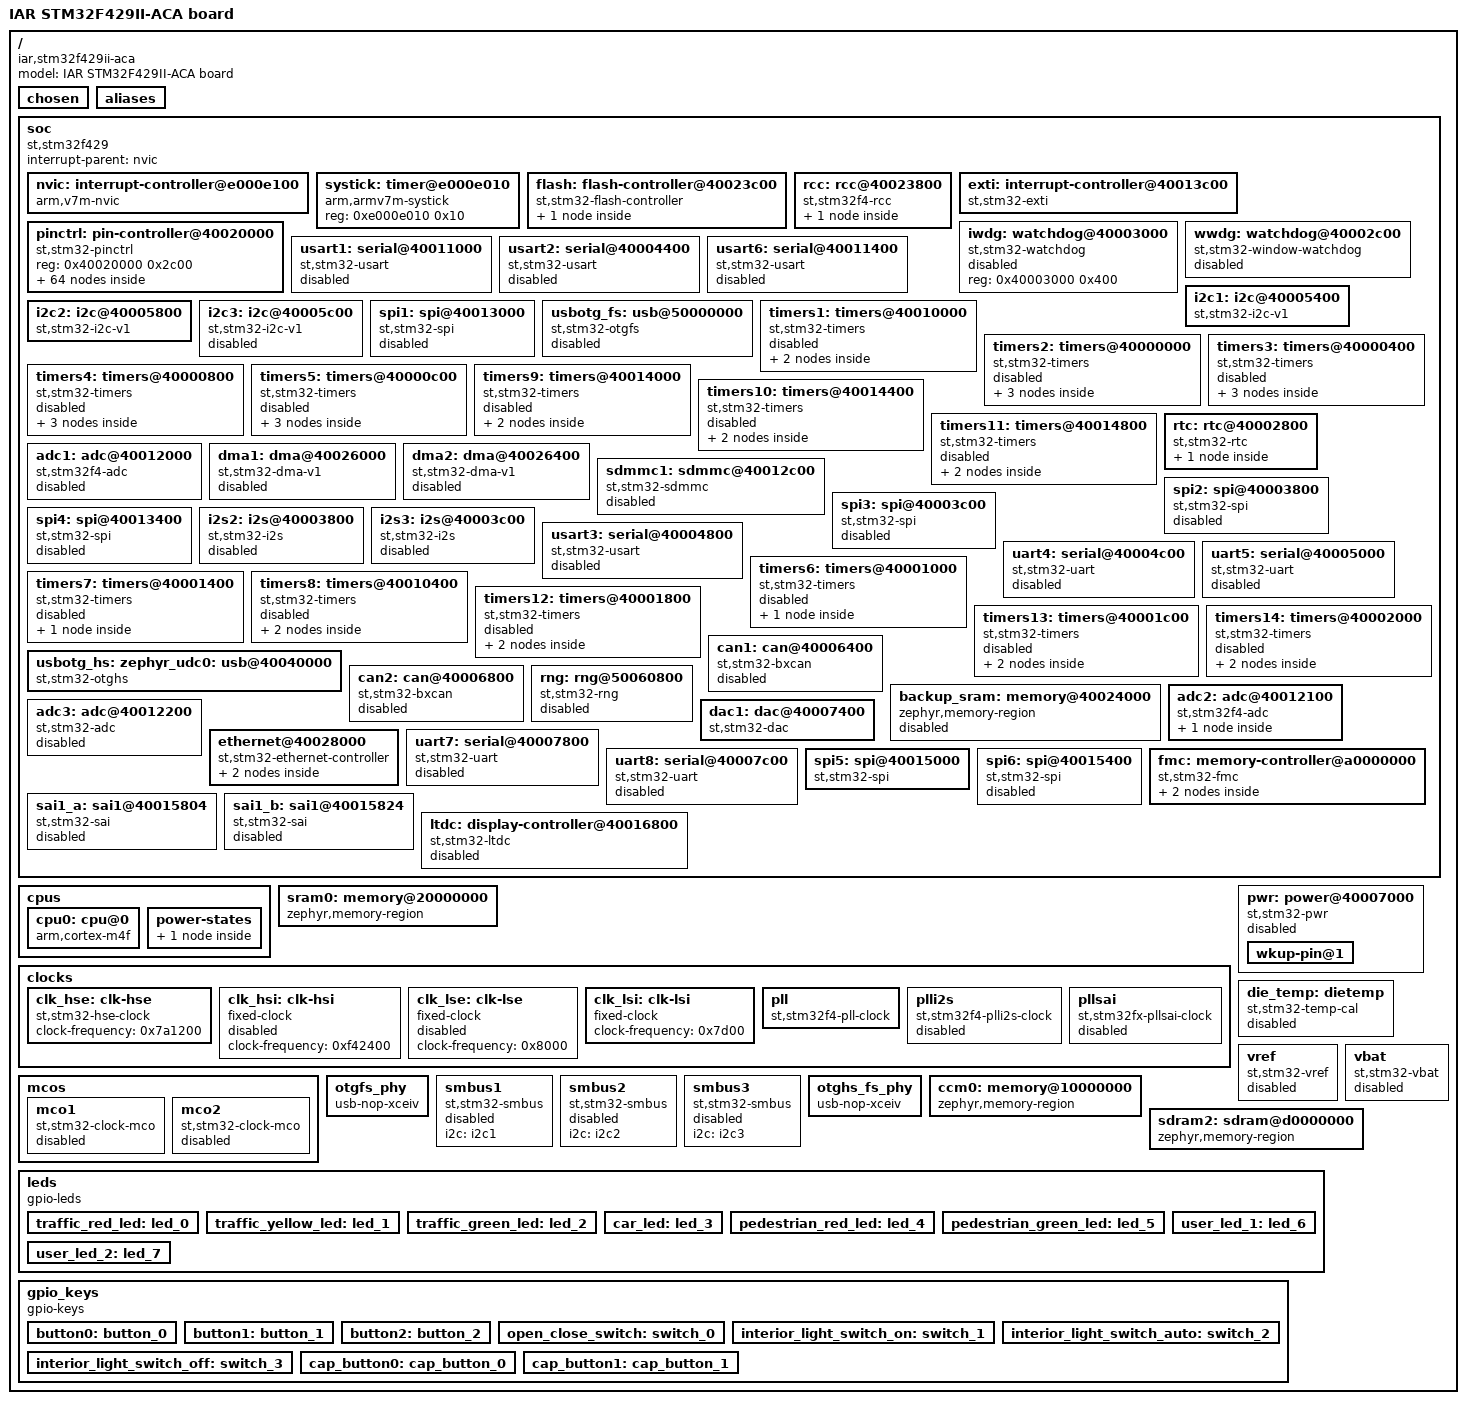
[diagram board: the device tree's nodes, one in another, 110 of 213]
/dts-v1/;

/* node '/' defined in zephyr/dts/common/skeleton.dtsi:9 */
/ {
	#address-cells = < 0x1 >;            /* in zephyr/dts/common/skeleton.dtsi:10 */
	#size-cells = < 0x1 >;               /* in zephyr/dts/common/skeleton.dtsi:11 */
	model = "IAR STM32F429II-ACA board"; /* in zephyr/boards/iar/stm32f429ii_aca/stm32f429ii_aca.dts:15 */
	compatible = "iar,stm32f429ii-aca";  /* in zephyr/boards/iar/stm32f429ii_aca/stm32f429ii_aca.dts:16 */

	/* node '/chosen' defined in zephyr/dts/common/skeleton.dtsi:13 */
	chosen {
		zephyr,flash-controller = &flash;  /* in zephyr/dts/arm/st/f4/stm32f4.dtsi:27 */
		zephyr,cortex-m-idle-timer = &rtc; /* in zephyr/dts/arm/st/f4/stm32f4.dtsi:28 */
		zephyr,entropy = &rng;             /* in zephyr/dts/arm/st/f4/stm32f405.dtsi:13 */
		zephyr,sram = &sram0;              /* in zephyr/boards/iar/stm32f429ii_aca/stm32f429ii_aca.dts:19 */
		zephyr,flash = &flash0;            /* in zephyr/boards/iar/stm32f429ii_aca/stm32f429ii_aca.dts:20 */
		zephyr,ccm = &ccm0;                /* in zephyr/boards/iar/stm32f429ii_aca/stm32f429ii_aca.dts:21 */
	};

	/* node '/aliases' defined in zephyr/dts/common/skeleton.dtsi:15 */
	aliases {
		led0 = &traffic_red_led;           /* in zephyr/boards/iar/stm32f429ii_aca/stm32f429ii_aca.dts:134 */
		led1 = &traffic_yellow_led;        /* in zephyr/boards/iar/stm32f429ii_aca/stm32f429ii_aca.dts:135 */
		led2 = &traffic_green_led;         /* in zephyr/boards/iar/stm32f429ii_aca/stm32f429ii_aca.dts:136 */
		led3 = &car_led;                   /* in zephyr/boards/iar/stm32f429ii_aca/stm32f429ii_aca.dts:137 */
		led4 = &pedestrian_red_led;        /* in zephyr/boards/iar/stm32f429ii_aca/stm32f429ii_aca.dts:138 */
		led5 = &pedestrian_green_led;      /* in zephyr/boards/iar/stm32f429ii_aca/stm32f429ii_aca.dts:139 */
		led6 = &user_led_1;                /* in zephyr/boards/iar/stm32f429ii_aca/stm32f429ii_aca.dts:140 */
		led7 = &user_led_2;                /* in zephyr/boards/iar/stm32f429ii_aca/stm32f429ii_aca.dts:141 */
		sw0 = &button0;                    /* in zephyr/boards/iar/stm32f429ii_aca/stm32f429ii_aca.dts:142 */
		sw1 = &button1;                    /* in zephyr/boards/iar/stm32f429ii_aca/stm32f429ii_aca.dts:143 */
		sw2 = &button2;                    /* in zephyr/boards/iar/stm32f429ii_aca/stm32f429ii_aca.dts:144 */
		sw3 = &open_close_switch;          /* in zephyr/boards/iar/stm32f429ii_aca/stm32f429ii_aca.dts:145 */
		sw4 = &interior_light_switch_on;   /* in zephyr/boards/iar/stm32f429ii_aca/stm32f429ii_aca.dts:146 */
		sw5 = &interior_light_switch_auto; /* in zephyr/boards/iar/stm32f429ii_aca/stm32f429ii_aca.dts:147 */
		sw6 = &interior_light_switch_off;  /* in zephyr/boards/iar/stm32f429ii_aca/stm32f429ii_aca.dts:148 */
		sw7 = &cap_button0;                /* in zephyr/boards/iar/stm32f429ii_aca/stm32f429ii_aca.dts:149 */
		sw8 = &cap_button1;                /* in zephyr/boards/iar/stm32f429ii_aca/stm32f429ii_aca.dts:150 */
	};

	/* node '/soc' defined in zephyr/dts/arm/armv7-m.dtsi:6 */
	soc {
		#address-cells = < 0x1 >;     /* in zephyr/dts/arm/armv7-m.dtsi:7 */
		#size-cells = < 0x1 >;        /* in zephyr/dts/arm/armv7-m.dtsi:8 */
		interrupt-parent = < &nvic >; /* in zephyr/dts/arm/armv7-m.dtsi:10 */
		ranges;                       /* in zephyr/dts/arm/armv7-m.dtsi:11 */
		compatible = "st,stm32f429",
		             "st,stm32f4",
		             "simple-bus";    /* in zephyr/dts/arm/st/f4/stm32f429.dtsi:12 */

		/* node '/soc/interrupt-controller@e000e100' defined in zephyr/dts/arm/armv7-m.dtsi:13 */
		nvic: interrupt-controller@e000e100 {
			#address-cells = < 0x1 >;            /* in zephyr/dts/arm/armv7-m.dtsi:14 */
			compatible = "arm,v7m-nvic";         /* in zephyr/dts/arm/armv7-m.dtsi:15 */
			reg = < 0xe000e100 0xc00 >;          /* in zephyr/dts/arm/armv7-m.dtsi:16 */
			interrupt-controller;                /* in zephyr/dts/arm/armv7-m.dtsi:17 */
			#interrupt-cells = < 0x2 >;          /* in zephyr/dts/arm/armv7-m.dtsi:18 */
			arm,num-irq-priority-bits = < 0x4 >; /* in zephyr/dts/arm/st/f4/stm32f4.dtsi:676 */
			phandle = < 0x1 >;                   /* in zephyr/dts/arm/armv7-m.dtsi:10 */
		};

		/* node '/soc/timer@e000e010' defined in zephyr/dts/arm/armv7-m.dtsi:21 */
		systick: timer@e000e010 {
			compatible = "arm,armv7m-systick"; /* in zephyr/dts/arm/armv7-m.dtsi:22 */
			reg = < 0xe000e010 0x10 >;         /* in zephyr/dts/arm/armv7-m.dtsi:23 */
		};

		/* node '/soc/flash-controller@40023c00' defined in zephyr/dts/arm/st/f4/stm32f4.dtsi:111 */
		flash: flash-controller@40023c00 {
			compatible = "st,stm32-flash-controller",
			             "st,stm32f4-flash-controller"; /* in zephyr/dts/arm/st/f4/stm32f4.dtsi:112 */
			reg = < 0x40023c00 0x400 >;                 /* in zephyr/dts/arm/st/f4/stm32f4.dtsi:113 */
			interrupts = < 0x4 0x0 >;                   /* in zephyr/dts/arm/st/f4/stm32f4.dtsi:114 */
			#address-cells = < 0x1 >;                   /* in zephyr/dts/arm/st/f4/stm32f4.dtsi:116 */
			#size-cells = < 0x1 >;                      /* in zephyr/dts/arm/st/f4/stm32f4.dtsi:117 */

			/* node '/soc/flash-controller@40023c00/flash@8000000' defined in zephyr/dts/arm/st/f4/stm32f4.dtsi:119 */
			flash0: flash@8000000 {
				compatible = "st,stm32f4-nv-flash",
				             "st,stm32-nv-flash",
				             "soc-nv-flash";        /* in zephyr/dts/arm/st/f4/stm32f4.dtsi:120 */
				write-block-size = < 0x1 >;         /* in zephyr/dts/arm/st/f4/stm32f4.dtsi:123 */
				max-erase-time = < 0xfa0 >;         /* in zephyr/dts/arm/st/f4/stm32f4.dtsi:125 */
				reg = < 0x8000000 0x200000 >;       /* in zephyr/dts/arm/st/f4/stm32f429Xi.dtsi:23 */
			};
		};

		/* node '/soc/rcc@40023800' defined in zephyr/dts/arm/st/f4/stm32f4.dtsi:129 */
		rcc: rcc@40023800 {
			#clock-cells = < 0x2 >;          /* in zephyr/dts/arm/st/f4/stm32f4.dtsi:131 */
			reg = < 0x40023800 0x400 >;      /* in zephyr/dts/arm/st/f4/stm32f4.dtsi:132 */
			compatible = "st,stm32f4-rcc";   /* in zephyr/dts/arm/st/f4/stm32f427.dtsi:25 */
			clocks = < &pll >;               /* in zephyr/boards/iar/stm32f429ii_aca/stm32f429ii_aca.dts:173 */
			clock-frequency = < 0xa037a00 >; /* in zephyr/boards/iar/stm32f429ii_aca/stm32f429ii_aca.dts:174 */
			ahb-prescaler = < 0x1 >;         /* in zephyr/boards/iar/stm32f429ii_aca/stm32f429ii_aca.dts:175 */
			apb1-prescaler = < 0x4 >;        /* in zephyr/boards/iar/stm32f429ii_aca/stm32f429ii_aca.dts:176 */
			apb2-prescaler = < 0x2 >;        /* in zephyr/boards/iar/stm32f429ii_aca/stm32f429ii_aca.dts:177 */
			phandle = < 0x3 >;               /* in zephyr/dts/arm/st/f4/stm32f4.dtsi:146 */

			/* node '/soc/rcc@40023800/reset-controller' defined in zephyr/dts/arm/st/f4/stm32f4.dtsi:134 */
			rctl: reset-controller {
				compatible = "st,stm32-rcc-rctl"; /* in zephyr/dts/arm/st/f4/stm32f4.dtsi:135 */
				#reset-cells = < 0x1 >;           /* in zephyr/dts/arm/st/f4/stm32f4.dtsi:136 */
				phandle = < 0x4 >;                /* in zephyr/dts/arm/st/f4/stm32f4.dtsi:245 */
			};
		};

		/* node '/soc/interrupt-controller@40013c00' defined in zephyr/dts/arm/st/f4/stm32f4.dtsi:140 */
		exti: interrupt-controller@40013c00 {
			compatible = "st,stm32-exti";  /* in zephyr/dts/arm/st/f4/stm32f4.dtsi:141 */
			interrupt-controller;          /* in zephyr/dts/arm/st/f4/stm32f4.dtsi:142 */
			#interrupt-cells = < 0x1 >;    /* in zephyr/dts/arm/st/f4/stm32f4.dtsi:143 */
			#address-cells = < 0x0 >;      /* in zephyr/dts/arm/st/f4/stm32f4.dtsi:144 */
			reg = < 0x40013c00 0x400 >;    /* in zephyr/dts/arm/st/f4/stm32f4.dtsi:145 */
			clocks = < &rcc 0x44 0x4000 >; /* in zephyr/dts/arm/st/f4/stm32f4.dtsi:146 */
			num-lines = < 0x20 >;          /* in zephyr/dts/arm/st/f4/stm32f4.dtsi:147 */
			interrupts = < 0x6 0x0 >,
			             < 0x7 0x0 >,
			             < 0x8 0x0 >,
			             < 0x9 0x0 >,
			             < 0xa 0x0 >,
			             < 0x17 0x0 >,
			             < 0x28 0x0 >;     /* in zephyr/dts/arm/st/f4/stm32f4.dtsi:148 */
			interrupt-names = "line0",
			                  "line1",
			                  "line2",
			                  "line3",
			                  "line4",
			                  "line5-9",
			                  "line10-15"; /* in zephyr/dts/arm/st/f4/stm32f4.dtsi:150 */
			line-ranges = < 0x0 0x1 >,
			              < 0x1 0x1 >,
			              < 0x2 0x1 >,
			              < 0x3 0x1 >,
			              < 0x4 0x1 >,
			              < 0x5 0x5 >,
			              < 0xa 0x6 >;     /* in zephyr/dts/arm/st/f4/stm32f4.dtsi:152 */
		};

		/* node '/soc/pin-controller@40020000' defined in zephyr/dts/arm/st/f4/stm32f4.dtsi:156 */
		pinctrl: pin-controller@40020000 {
			compatible = "st,stm32-pinctrl"; /* in zephyr/dts/arm/st/f4/stm32f4.dtsi:157 */
			#address-cells = < 0x1 >;        /* in zephyr/dts/arm/st/f4/stm32f4.dtsi:158 */
			#size-cells = < 0x1 >;           /* in zephyr/dts/arm/st/f4/stm32f4.dtsi:159 */
			reg = < 0x40020000 0x2c00 >;     /* in zephyr/dts/arm/st/f4/stm32f427.dtsi:29 */

			/* node '/soc/pin-controller@40020000/gpio@40020000' defined in zephyr/dts/arm/st/f4/stm32f4.dtsi:162 */
			gpioa: gpio@40020000 {
				compatible = "st,stm32-gpio"; /* in zephyr/dts/arm/st/f4/stm32f4.dtsi:163 */
				gpio-controller;              /* in zephyr/dts/arm/st/f4/stm32f4.dtsi:164 */
				#gpio-cells = < 0x2 >;        /* in zephyr/dts/arm/st/f4/stm32f4.dtsi:165 */
				reg = < 0x40020000 0x400 >;   /* in zephyr/dts/arm/st/f4/stm32f4.dtsi:166 */
				clocks = < &rcc 0x30 0x1 >;   /* in zephyr/dts/arm/st/f4/stm32f4.dtsi:167 */
				phandle = < 0x41 >;           /* in zephyr/dts/arm/st/f4/stm32f4.dtsi:615 */
			};

			/* node '/soc/pin-controller@40020000/gpio@40020400' defined in zephyr/dts/arm/st/f4/stm32f4.dtsi:170 */
			gpiob: gpio@40020400 {
				compatible = "st,stm32-gpio"; /* in zephyr/dts/arm/st/f4/stm32f4.dtsi:171 */
				gpio-controller;              /* in zephyr/dts/arm/st/f4/stm32f4.dtsi:172 */
				#gpio-cells = < 0x2 >;        /* in zephyr/dts/arm/st/f4/stm32f4.dtsi:173 */
				reg = < 0x40020400 0x400 >;   /* in zephyr/dts/arm/st/f4/stm32f4.dtsi:174 */
				clocks = < &rcc 0x30 0x2 >;   /* in zephyr/dts/arm/st/f4/stm32f4.dtsi:175 */
			};

			/* node '/soc/pin-controller@40020000/gpio@40020800' defined in zephyr/dts/arm/st/f4/stm32f4.dtsi:178 */
			gpioc: gpio@40020800 {
				compatible = "st,stm32-gpio"; /* in zephyr/dts/arm/st/f4/stm32f4.dtsi:179 */
				gpio-controller;              /* in zephyr/dts/arm/st/f4/stm32f4.dtsi:180 */
				#gpio-cells = < 0x2 >;        /* in zephyr/dts/arm/st/f4/stm32f4.dtsi:181 */
				reg = < 0x40020800 0x400 >;   /* in zephyr/dts/arm/st/f4/stm32f4.dtsi:182 */
				clocks = < &rcc 0x30 0x4 >;   /* in zephyr/dts/arm/st/f4/stm32f4.dtsi:183 */
				phandle = < 0x15 >;           /* in zephyr/boards/iar/stm32f429ii_aca/stm32f429ii_aca.dts:205 */
			};

			/* node '/soc/pin-controller@40020000/gpio@40020c00' defined in zephyr/dts/arm/st/f4/stm32f4.dtsi:186 */
			gpiod: gpio@40020c00 {
				compatible = "st,stm32-gpio"; /* in zephyr/dts/arm/st/f4/stm32f4.dtsi:187 */
				gpio-controller;              /* in zephyr/dts/arm/st/f4/stm32f4.dtsi:188 */
				#gpio-cells = < 0x2 >;        /* in zephyr/dts/arm/st/f4/stm32f4.dtsi:189 */
				reg = < 0x40020c00 0x400 >;   /* in zephyr/dts/arm/st/f4/stm32f4.dtsi:190 */
				clocks = < &rcc 0x30 0x8 >;   /* in zephyr/dts/arm/st/f4/stm32f4.dtsi:191 */
				phandle = < 0x46 >;           /* in zephyr/boards/iar/stm32f429ii_aca/stm32f429ii_aca.dts:40 */
			};

			/* node '/soc/pin-controller@40020000/gpio@40021000' defined in zephyr/dts/arm/st/f4/stm32f4.dtsi:194 */
			gpioe: gpio@40021000 {
				compatible = "st,stm32-gpio"; /* in zephyr/dts/arm/st/f4/stm32f4.dtsi:195 */
				gpio-controller;              /* in zephyr/dts/arm/st/f4/stm32f4.dtsi:196 */
				#gpio-cells = < 0x2 >;        /* in zephyr/dts/arm/st/f4/stm32f4.dtsi:197 */
				reg = < 0x40021000 0x400 >;   /* in zephyr/dts/arm/st/f4/stm32f4.dtsi:198 */
				clocks = < &rcc 0x30 0x10 >;  /* in zephyr/dts/arm/st/f4/stm32f4.dtsi:199 */
			};

			/* node '/soc/pin-controller@40020000/gpio@40021400' defined in zephyr/dts/arm/st/f4/stm32f4.dtsi:202 */
			gpiof: gpio@40021400 {
				compatible = "st,stm32-gpio"; /* in zephyr/dts/arm/st/f4/stm32f405.dtsi:27 */
				gpio-controller;              /* in zephyr/dts/arm/st/f4/stm32f405.dtsi:28 */
				#gpio-cells = < 0x2 >;        /* in zephyr/dts/arm/st/f4/stm32f405.dtsi:29 */
				reg = < 0x40021400 0x400 >;   /* in zephyr/dts/arm/st/f4/stm32f405.dtsi:30 */
				clocks = < &rcc 0x30 0x20 >;  /* in zephyr/dts/arm/st/f4/stm32f405.dtsi:31 */
			};

			/* node '/soc/pin-controller@40020000/gpio@40021800' defined in zephyr/dts/arm/st/f4/stm32f4.dtsi:210 */
			gpiog: gpio@40021800 {
				compatible = "st,stm32-gpio"; /* in zephyr/dts/arm/st/f4/stm32f405.dtsi:35 */
				gpio-controller;              /* in zephyr/dts/arm/st/f4/stm32f405.dtsi:36 */
				#gpio-cells = < 0x2 >;        /* in zephyr/dts/arm/st/f4/stm32f405.dtsi:37 */
				reg = < 0x40021800 0x400 >;   /* in zephyr/dts/arm/st/f4/stm32f405.dtsi:38 */
				clocks = < &rcc 0x30 0x40 >;  /* in zephyr/dts/arm/st/f4/stm32f405.dtsi:39 */
				phandle = < 0x47 >;           /* in zephyr/boards/iar/stm32f429ii_aca/stm32f429ii_aca.dts:92 */
			};

			/* node '/soc/pin-controller@40020000/gpio@40021c00' defined in zephyr/dts/arm/st/f4/stm32f4.dtsi:218 */
			gpioh: gpio@40021c00 {
				compatible = "st,stm32-gpio"; /* in zephyr/dts/arm/st/f4/stm32f4.dtsi:219 */
				gpio-controller;              /* in zephyr/dts/arm/st/f4/stm32f4.dtsi:220 */
				#gpio-cells = < 0x2 >;        /* in zephyr/dts/arm/st/f4/stm32f4.dtsi:221 */
				reg = < 0x40021c00 0x400 >;   /* in zephyr/dts/arm/st/f4/stm32f4.dtsi:222 */
				clocks = < &rcc 0x30 0x80 >;  /* in zephyr/dts/arm/st/f4/stm32f4.dtsi:223 */
				phandle = < 0x49 >;           /* in zephyr/boards/iar/stm32f429ii_aca/stm32f429ii_aca.dts:122 */
			};

			/* node '/soc/pin-controller@40020000/gpio@40022000' defined in zephyr/dts/arm/st/f4/stm32f405.dtsi:42 */
			gpioi: gpio@40022000 {
				compatible = "st,stm32-gpio"; /* in zephyr/dts/arm/st/f4/stm32f405.dtsi:43 */
				gpio-controller;              /* in zephyr/dts/arm/st/f4/stm32f405.dtsi:44 */
				#gpio-cells = < 0x2 >;        /* in zephyr/dts/arm/st/f4/stm32f405.dtsi:45 */
				reg = < 0x40022000 0x400 >;   /* in zephyr/dts/arm/st/f4/stm32f405.dtsi:46 */
				clocks = < &rcc 0x30 0x100 >; /* in zephyr/dts/arm/st/f4/stm32f405.dtsi:47 */
				phandle = < 0x48 >;           /* in zephyr/boards/iar/stm32f429ii_aca/stm32f429ii_aca.dts:98 */
			};

			/* node '/soc/pin-controller@40020000/gpio@40022400' defined in zephyr/dts/arm/st/f4/stm32f427.dtsi:31 */
			gpioj: gpio@40022400 {
				compatible = "st,stm32-gpio"; /* in zephyr/dts/arm/st/f4/stm32f427.dtsi:32 */
				gpio-controller;              /* in zephyr/dts/arm/st/f4/stm32f427.dtsi:33 */
				#gpio-cells = < 0x2 >;        /* in zephyr/dts/arm/st/f4/stm32f427.dtsi:34 */
				reg = < 0x40022400 0x400 >;   /* in zephyr/dts/arm/st/f4/stm32f427.dtsi:35 */
				clocks = < &rcc 0x30 0x200 >; /* in zephyr/dts/arm/st/f4/stm32f427.dtsi:36 */
			};

			/* node '/soc/pin-controller@40020000/gpio@40022800' defined in zephyr/dts/arm/st/f4/stm32f427.dtsi:39 */
			gpiok: gpio@40022800 {
				compatible = "st,stm32-gpio"; /* in zephyr/dts/arm/st/f4/stm32f427.dtsi:40 */
				gpio-controller;              /* in zephyr/dts/arm/st/f4/stm32f427.dtsi:41 */
				#gpio-cells = < 0x2 >;        /* in zephyr/dts/arm/st/f4/stm32f427.dtsi:42 */
				reg = < 0x40022800 0x400 >;   /* in zephyr/dts/arm/st/f4/stm32f427.dtsi:43 */
				clocks = < &rcc 0x30 0x400 >; /* in zephyr/dts/arm/st/f4/stm32f427.dtsi:44 */
			};

			/* node '/soc/pin-controller@40020000/adc2_in6_pa6' defined in modules/hal/stm32/dts/st/f4/stm32f429iitx-pinctrl.dtsi:103 */
			adc2_in6_pa6: adc2_in6_pa6 {
				pinmux = < 0xd0 >; /* in modules/hal/stm32/dts/st/f4/stm32f429iitx-pinctrl.dtsi:104 */
				phandle = < 0xf >; /* in zephyr/boards/iar/stm32f429ii_aca/stm32f429ii_aca.dts:249 */
			};

			/* node '/soc/pin-controller@40020000/dac_out2_pa5' defined in modules/hal/stm32/dts/st/f4/stm32f429iitx-pinctrl.dtsi:833 */
			dac_out2_pa5: dac_out2_pa5 {
				pinmux = < 0xb0 >;  /* in modules/hal/stm32/dts/st/f4/stm32f429iitx-pinctrl.dtsi:834 */
				phandle = < 0x10 >; /* in zephyr/boards/iar/stm32f429ii_aca/stm32f429ii_aca.dts:267 */
			};

			/* node '/soc/pin-controller@40020000/fmc_sdnwe_pc0' defined in modules/hal/stm32/dts/st/f4/stm32f429iitx-pinctrl.dtsi:1256 */
			fmc_sdnwe_pc0: fmc_sdnwe_pc0 {
				pinmux = < 0x40c >;            /* in modules/hal/stm32/dts/st/f4/stm32f429iitx-pinctrl.dtsi:1257 */
				bias-pull-up;                  /* in modules/hal/stm32/dts/st/f4/stm32f429iitx-pinctrl.dtsi:1258 */
				slew-rate = "very-high-speed"; /* in modules/hal/stm32/dts/st/f4/stm32f429iitx-pinctrl.dtsi:1259 */
				phandle = < 0x19 >;            /* in zephyr/boards/iar/stm32f429ii_aca/stm32f429ii_aca.dts:210 */
			};

			/* node '/soc/pin-controller@40020000/fmc_sdne0_pc2' defined in modules/hal/stm32/dts/st/f4/stm32f429iitx-pinctrl.dtsi:1262 */
			fmc_sdne0_pc2: fmc_sdne0_pc2 {
				pinmux = < 0x44c >;            /* in modules/hal/stm32/dts/st/f4/stm32f429iitx-pinctrl.dtsi:1263 */
				bias-pull-up;                  /* in modules/hal/stm32/dts/st/f4/stm32f429iitx-pinctrl.dtsi:1264 */
				slew-rate = "very-high-speed"; /* in modules/hal/stm32/dts/st/f4/stm32f429iitx-pinctrl.dtsi:1265 */
				phandle = < 0x1b >;            /* in zephyr/boards/iar/stm32f429ii_aca/stm32f429ii_aca.dts:210 */
			};

			/* node '/soc/pin-controller@40020000/fmc_sdcke0_pc3' defined in modules/hal/stm32/dts/st/f4/stm32f429iitx-pinctrl.dtsi:1268 */
			fmc_sdcke0_pc3: fmc_sdcke0_pc3 {
				pinmux = < 0x46c >;            /* in modules/hal/stm32/dts/st/f4/stm32f429iitx-pinctrl.dtsi:1269 */
				bias-pull-up;                  /* in modules/hal/stm32/dts/st/f4/stm32f429iitx-pinctrl.dtsi:1270 */
				slew-rate = "very-high-speed"; /* in modules/hal/stm32/dts/st/f4/stm32f429iitx-pinctrl.dtsi:1271 */
				phandle = < 0x1a >;            /* in zephyr/boards/iar/stm32f429ii_aca/stm32f429ii_aca.dts:210 */
			};

			/* node '/soc/pin-controller@40020000/fmc_d2_pd0' defined in modules/hal/stm32/dts/st/f4/stm32f429iitx-pinctrl.dtsi:1274 */
			fmc_d2_pd0: fmc_d2_pd0 {
				pinmux = < 0x60c >;            /* in modules/hal/stm32/dts/st/f4/stm32f429iitx-pinctrl.dtsi:1275 */
				bias-pull-up;                  /* in modules/hal/stm32/dts/st/f4/stm32f429iitx-pinctrl.dtsi:1276 */
				slew-rate = "very-high-speed"; /* in modules/hal/stm32/dts/st/f4/stm32f429iitx-pinctrl.dtsi:1277 */
				phandle = < 0x30 >;            /* in zephyr/boards/iar/stm32f429ii_aca/stm32f429ii_aca.dts:210 */
			};

			/* node '/soc/pin-controller@40020000/fmc_d3_pd1' defined in modules/hal/stm32/dts/st/f4/stm32f429iitx-pinctrl.dtsi:1280 */
			fmc_d3_pd1: fmc_d3_pd1 {
				pinmux = < 0x62c >;            /* in modules/hal/stm32/dts/st/f4/stm32f429iitx-pinctrl.dtsi:1281 */
				bias-pull-up;                  /* in modules/hal/stm32/dts/st/f4/stm32f429iitx-pinctrl.dtsi:1282 */
				slew-rate = "very-high-speed"; /* in modules/hal/stm32/dts/st/f4/stm32f429iitx-pinctrl.dtsi:1283 */
				phandle = < 0x31 >;            /* in zephyr/boards/iar/stm32f429ii_aca/stm32f429ii_aca.dts:210 */
			};

			/* node '/soc/pin-controller@40020000/fmc_d13_pd8' defined in modules/hal/stm32/dts/st/f4/stm32f429iitx-pinctrl.dtsi:1316 */
			fmc_d13_pd8: fmc_d13_pd8 {
				pinmux = < 0x70c >;            /* in modules/hal/stm32/dts/st/f4/stm32f429iitx-pinctrl.dtsi:1317 */
				bias-pull-up;                  /* in modules/hal/stm32/dts/st/f4/stm32f429iitx-pinctrl.dtsi:1318 */
				slew-rate = "very-high-speed"; /* in modules/hal/stm32/dts/st/f4/stm32f429iitx-pinctrl.dtsi:1319 */
				phandle = < 0x3b >;            /* in zephyr/boards/iar/stm32f429ii_aca/stm32f429ii_aca.dts:210 */
			};

			/* node '/soc/pin-controller@40020000/fmc_d14_pd9' defined in modules/hal/stm32/dts/st/f4/stm32f429iitx-pinctrl.dtsi:1322 */
			fmc_d14_pd9: fmc_d14_pd9 {
				pinmux = < 0x72c >;            /* in modules/hal/stm32/dts/st/f4/stm32f429iitx-pinctrl.dtsi:1323 */
				bias-pull-up;                  /* in modules/hal/stm32/dts/st/f4/stm32f429iitx-pinctrl.dtsi:1324 */
				slew-rate = "very-high-speed"; /* in modules/hal/stm32/dts/st/f4/stm32f429iitx-pinctrl.dtsi:1325 */
				phandle = < 0x3c >;            /* in zephyr/boards/iar/stm32f429ii_aca/stm32f429ii_aca.dts:210 */
			};

			/* node '/soc/pin-controller@40020000/fmc_d15_pd10' defined in modules/hal/stm32/dts/st/f4/stm32f429iitx-pinctrl.dtsi:1328 */
			fmc_d15_pd10: fmc_d15_pd10 {
				pinmux = < 0x74c >;            /* in modules/hal/stm32/dts/st/f4/stm32f429iitx-pinctrl.dtsi:1329 */
				bias-pull-up;                  /* in modules/hal/stm32/dts/st/f4/stm32f429iitx-pinctrl.dtsi:1330 */
				slew-rate = "very-high-speed"; /* in modules/hal/stm32/dts/st/f4/stm32f429iitx-pinctrl.dtsi:1331 */
				phandle = < 0x3d >;            /* in zephyr/boards/iar/stm32f429ii_aca/stm32f429ii_aca.dts:210 */
			};

			/* node '/soc/pin-controller@40020000/fmc_d0_pd14' defined in modules/hal/stm32/dts/st/f4/stm32f429iitx-pinctrl.dtsi:1364 */
			fmc_d0_pd14: fmc_d0_pd14 {
				pinmux = < 0x7cc >;            /* in modules/hal/stm32/dts/st/f4/stm32f429iitx-pinctrl.dtsi:1365 */
				bias-pull-up;                  /* in modules/hal/stm32/dts/st/f4/stm32f429iitx-pinctrl.dtsi:1366 */
				slew-rate = "very-high-speed"; /* in modules/hal/stm32/dts/st/f4/stm32f429iitx-pinctrl.dtsi:1367 */
				phandle = < 0x2e >;            /* in zephyr/boards/iar/stm32f429ii_aca/stm32f429ii_aca.dts:210 */
			};

			/* node '/soc/pin-controller@40020000/fmc_d1_pd15' defined in modules/hal/stm32/dts/st/f4/stm32f429iitx-pinctrl.dtsi:1370 */
			fmc_d1_pd15: fmc_d1_pd15 {
				pinmux = < 0x7ec >;            /* in modules/hal/stm32/dts/st/f4/stm32f429iitx-pinctrl.dtsi:1371 */
				bias-pull-up;                  /* in modules/hal/stm32/dts/st/f4/stm32f429iitx-pinctrl.dtsi:1372 */
				slew-rate = "very-high-speed"; /* in modules/hal/stm32/dts/st/f4/stm32f429iitx-pinctrl.dtsi:1373 */
				phandle = < 0x2f >;            /* in zephyr/boards/iar/stm32f429ii_aca/stm32f429ii_aca.dts:210 */
			};

			/* node '/soc/pin-controller@40020000/fmc_nbl0_pe0' defined in modules/hal/stm32/dts/st/f4/stm32f429iitx-pinctrl.dtsi:1376 */
			fmc_nbl0_pe0: fmc_nbl0_pe0 {
				pinmux = < 0x80c >;            /* in modules/hal/stm32/dts/st/f4/stm32f429iitx-pinctrl.dtsi:1377 */
				bias-pull-up;                  /* in modules/hal/stm32/dts/st/f4/stm32f429iitx-pinctrl.dtsi:1378 */
				slew-rate = "very-high-speed"; /* in modules/hal/stm32/dts/st/f4/stm32f429iitx-pinctrl.dtsi:1379 */
				phandle = < 0x16 >;            /* in zephyr/boards/iar/stm32f429ii_aca/stm32f429ii_aca.dts:210 */
			};

			/* node '/soc/pin-controller@40020000/fmc_nbl1_pe1' defined in modules/hal/stm32/dts/st/f4/stm32f429iitx-pinctrl.dtsi:1382 */
			fmc_nbl1_pe1: fmc_nbl1_pe1 {
				pinmux = < 0x82c >;            /* in modules/hal/stm32/dts/st/f4/stm32f429iitx-pinctrl.dtsi:1383 */
				bias-pull-up;                  /* in modules/hal/stm32/dts/st/f4/stm32f429iitx-pinctrl.dtsi:1384 */
				slew-rate = "very-high-speed"; /* in modules/hal/stm32/dts/st/f4/stm32f429iitx-pinctrl.dtsi:1385 */
				phandle = < 0x17 >;            /* in zephyr/boards/iar/stm32f429ii_aca/stm32f429ii_aca.dts:210 */
			};

			/* node '/soc/pin-controller@40020000/fmc_d4_pe7' defined in modules/hal/stm32/dts/st/f4/stm32f429iitx-pinctrl.dtsi:1418 */
			fmc_d4_pe7: fmc_d4_pe7 {
				pinmux = < 0x8ec >;            /* in modules/hal/stm32/dts/st/f4/stm32f429iitx-pinctrl.dtsi:1419 */
				bias-pull-up;                  /* in modules/hal/stm32/dts/st/f4/stm32f429iitx-pinctrl.dtsi:1420 */
				slew-rate = "very-high-speed"; /* in modules/hal/stm32/dts/st/f4/stm32f429iitx-pinctrl.dtsi:1421 */
				phandle = < 0x32 >;            /* in zephyr/boards/iar/stm32f429ii_aca/stm32f429ii_aca.dts:210 */
			};

			/* node '/soc/pin-controller@40020000/fmc_d5_pe8' defined in modules/hal/stm32/dts/st/f4/stm32f429iitx-pinctrl.dtsi:1424 */
			fmc_d5_pe8: fmc_d5_pe8 {
				pinmux = < 0x90c >;            /* in modules/hal/stm32/dts/st/f4/stm32f429iitx-pinctrl.dtsi:1425 */
				bias-pull-up;                  /* in modules/hal/stm32/dts/st/f4/stm32f429iitx-pinctrl.dtsi:1426 */
				slew-rate = "very-high-speed"; /* in modules/hal/stm32/dts/st/f4/stm32f429iitx-pinctrl.dtsi:1427 */
				phandle = < 0x33 >;            /* in zephyr/boards/iar/stm32f429ii_aca/stm32f429ii_aca.dts:210 */
			};

			/* node '/soc/pin-controller@40020000/fmc_d6_pe9' defined in modules/hal/stm32/dts/st/f4/stm32f429iitx-pinctrl.dtsi:1430 */
			fmc_d6_pe9: fmc_d6_pe9 {
				pinmux = < 0x92c >;            /* in modules/hal/stm32/dts/st/f4/stm32f429iitx-pinctrl.dtsi:1431 */
				bias-pull-up;                  /* in modules/hal/stm32/dts/st/f4/stm32f429iitx-pinctrl.dtsi:1432 */
				slew-rate = "very-high-speed"; /* in modules/hal/stm32/dts/st/f4/stm32f429iitx-pinctrl.dtsi:1433 */
				phandle = < 0x34 >;            /* in zephyr/boards/iar/stm32f429ii_aca/stm32f429ii_aca.dts:210 */
			};

			/* node '/soc/pin-controller@40020000/fmc_d7_pe10' defined in modules/hal/stm32/dts/st/f4/stm32f429iitx-pinctrl.dtsi:1436 */
			fmc_d7_pe10: fmc_d7_pe10 {
				pinmux = < 0x94c >;            /* in modules/hal/stm32/dts/st/f4/stm32f429iitx-pinctrl.dtsi:1437 */
				bias-pull-up;                  /* in modules/hal/stm32/dts/st/f4/stm32f429iitx-pinctrl.dtsi:1438 */
				slew-rate = "very-high-speed"; /* in modules/hal/stm32/dts/st/f4/stm32f429iitx-pinctrl.dtsi:1439 */
				phandle = < 0x35 >;            /* in zephyr/boards/iar/stm32f429ii_aca/stm32f429ii_aca.dts:210 */
			};

			/* node '/soc/pin-controller@40020000/fmc_d8_pe11' defined in modules/hal/stm32/dts/st/f4/stm32f429iitx-pinctrl.dtsi:1442 */
			fmc_d8_pe11: fmc_d8_pe11 {
				pinmux = < 0x96c >;            /* in modules/hal/stm32/dts/st/f4/stm32f429iitx-pinctrl.dtsi:1443 */
				bias-pull-up;                  /* in modules/hal/stm32/dts/st/f4/stm32f429iitx-pinctrl.dtsi:1444 */
				slew-rate = "very-high-speed"; /* in modules/hal/stm32/dts/st/f4/stm32f429iitx-pinctrl.dtsi:1445 */
				phandle = < 0x36 >;            /* in zephyr/boards/iar/stm32f429ii_aca/stm32f429ii_aca.dts:210 */
			};

			/* node '/soc/pin-controller@40020000/fmc_d9_pe12' defined in modules/hal/stm32/dts/st/f4/stm32f429iitx-pinctrl.dtsi:1448 */
			fmc_d9_pe12: fmc_d9_pe12 {
				pinmux = < 0x98c >;            /* in modules/hal/stm32/dts/st/f4/stm32f429iitx-pinctrl.dtsi:1449 */
				bias-pull-up;                  /* in modules/hal/stm32/dts/st/f4/stm32f429iitx-pinctrl.dtsi:1450 */
				slew-rate = "very-high-speed"; /* in modules/hal/stm32/dts/st/f4/stm32f429iitx-pinctrl.dtsi:1451 */
				phandle = < 0x37 >;            /* in zephyr/boards/iar/stm32f429ii_aca/stm32f429ii_aca.dts:210 */
			};

			/* node '/soc/pin-controller@40020000/fmc_d10_pe13' defined in modules/hal/stm32/dts/st/f4/stm32f429iitx-pinctrl.dtsi:1454 */
			fmc_d10_pe13: fmc_d10_pe13 {
				pinmux = < 0x9ac >;            /* in modules/hal/stm32/dts/st/f4/stm32f429iitx-pinctrl.dtsi:1455 */
				bias-pull-up;                  /* in modules/hal/stm32/dts/st/f4/stm32f429iitx-pinctrl.dtsi:1456 */
				slew-rate = "very-high-speed"; /* in modules/hal/stm32/dts/st/f4/stm32f429iitx-pinctrl.dtsi:1457 */
				phandle = < 0x38 >;            /* in zephyr/boards/iar/stm32f429ii_aca/stm32f429ii_aca.dts:210 */
			};

			/* node '/soc/pin-controller@40020000/fmc_d11_pe14' defined in modules/hal/stm32/dts/st/f4/stm32f429iitx-pinctrl.dtsi:1460 */
			fmc_d11_pe14: fmc_d11_pe14 {
				pinmux = < 0x9cc >;            /* in modules/hal/stm32/dts/st/f4/stm32f429iitx-pinctrl.dtsi:1461 */
				bias-pull-up;                  /* in modules/hal/stm32/dts/st/f4/stm32f429iitx-pinctrl.dtsi:1462 */
				slew-rate = "very-high-speed"; /* in modules/hal/stm32/dts/st/f4/stm32f429iitx-pinctrl.dtsi:1463 */
				phandle = < 0x39 >;            /* in zephyr/boards/iar/stm32f429ii_aca/stm32f429ii_aca.dts:210 */
			};

			/* node '/soc/pin-controller@40020000/fmc_d12_pe15' defined in modules/hal/stm32/dts/st/f4/stm32f429iitx-pinctrl.dtsi:1466 */
			fmc_d12_pe15: fmc_d12_pe15 {
				pinmux = < 0x9ec >;            /* in modules/hal/stm32/dts/st/f4/stm32f429iitx-pinctrl.dtsi:1467 */
				bias-pull-up;                  /* in modules/hal/stm32/dts/st/f4/stm32f429iitx-pinctrl.dtsi:1468 */
				slew-rate = "very-high-speed"; /* in modules/hal/stm32/dts/st/f4/stm32f429iitx-pinctrl.dtsi:1469 */
				phandle = < 0x3a >;            /* in zephyr/boards/iar/stm32f429ii_aca/stm32f429ii_aca.dts:210 */
			};

			/* node '/soc/pin-controller@40020000/fmc_a0_pf0' defined in modules/hal/stm32/dts/st/f4/stm32f429iitx-pinctrl.dtsi:1472 */
			fmc_a0_pf0: fmc_a0_pf0 {
				pinmux = < 0xa0c >;            /* in modules/hal/stm32/dts/st/f4/stm32f429iitx-pinctrl.dtsi:1473 */
				bias-pull-up;                  /* in modules/hal/stm32/dts/st/f4/stm32f429iitx-pinctrl.dtsi:1474 */
				slew-rate = "very-high-speed"; /* in modules/hal/stm32/dts/st/f4/stm32f429iitx-pinctrl.dtsi:1475 */
				phandle = < 0x1e >;            /* in zephyr/boards/iar/stm32f429ii_aca/stm32f429ii_aca.dts:210 */
			};

			/* node '/soc/pin-controller@40020000/fmc_a1_pf1' defined in modules/hal/stm32/dts/st/f4/stm32f429iitx-pinctrl.dtsi:1478 */
			fmc_a1_pf1: fmc_a1_pf1 {
				pinmux = < 0xa2c >;            /* in modules/hal/stm32/dts/st/f4/stm32f429iitx-pinctrl.dtsi:1479 */
				bias-pull-up;                  /* in modules/hal/stm32/dts/st/f4/stm32f429iitx-pinctrl.dtsi:1480 */
				slew-rate = "very-high-speed"; /* in modules/hal/stm32/dts/st/f4/stm32f429iitx-pinctrl.dtsi:1481 */
				phandle = < 0x1f >;            /* in zephyr/boards/iar/stm32f429ii_aca/stm32f429ii_aca.dts:210 */
			};

			/* node '/soc/pin-controller@40020000/fmc_a2_pf2' defined in modules/hal/stm32/dts/st/f4/stm32f429iitx-pinctrl.dtsi:1484 */
			fmc_a2_pf2: fmc_a2_pf2 {
				pinmux = < 0xa4c >;            /* in modules/hal/stm32/dts/st/f4/stm32f429iitx-pinctrl.dtsi:1485 */
				bias-pull-up;                  /* in modules/hal/stm32/dts/st/f4/stm32f429iitx-pinctrl.dtsi:1486 */
				slew-rate = "very-high-speed"; /* in modules/hal/stm32/dts/st/f4/stm32f429iitx-pinctrl.dtsi:1487 */
				phandle = < 0x20 >;            /* in zephyr/boards/iar/stm32f429ii_aca/stm32f429ii_aca.dts:210 */
			};

			/* node '/soc/pin-controller@40020000/fmc_a3_pf3' defined in modules/hal/stm32/dts/st/f4/stm32f429iitx-pinctrl.dtsi:1490 */
			fmc_a3_pf3: fmc_a3_pf3 {
				pinmux = < 0xa6c >;            /* in modules/hal/stm32/dts/st/f4/stm32f429iitx-pinctrl.dtsi:1491 */
				bias-pull-up;                  /* in modules/hal/stm32/dts/st/f4/stm32f429iitx-pinctrl.dtsi:1492 */
				slew-rate = "very-high-speed"; /* in modules/hal/stm32/dts/st/f4/stm32f429iitx-pinctrl.dtsi:1493 */
				phandle = < 0x21 >;            /* in zephyr/boards/iar/stm32f429ii_aca/stm32f429ii_aca.dts:210 */
			};

			/* node '/soc/pin-controller@40020000/fmc_a4_pf4' defined in modules/hal/stm32/dts/st/f4/stm32f429iitx-pinctrl.dtsi:1496 */
			fmc_a4_pf4: fmc_a4_pf4 {
				pinmux = < 0xa8c >;            /* in modules/hal/stm32/dts/st/f4/stm32f429iitx-pinctrl.dtsi:1497 */
				bias-pull-up;                  /* in modules/hal/stm32/dts/st/f4/stm32f429iitx-pinctrl.dtsi:1498 */
				slew-rate = "very-high-speed"; /* in modules/hal/stm32/dts/st/f4/stm32f429iitx-pinctrl.dtsi:1499 */
				phandle = < 0x22 >;            /* in zephyr/boards/iar/stm32f429ii_aca/stm32f429ii_aca.dts:210 */
			};

			/* node '/soc/pin-controller@40020000/fmc_a5_pf5' defined in modules/hal/stm32/dts/st/f4/stm32f429iitx-pinctrl.dtsi:1502 */
			fmc_a5_pf5: fmc_a5_pf5 {
				pinmux = < 0xaac >;            /* in modules/hal/stm32/dts/st/f4/stm32f429iitx-pinctrl.dtsi:1503 */
				bias-pull-up;                  /* in modules/hal/stm32/dts/st/f4/stm32f429iitx-pinctrl.dtsi:1504 */
				slew-rate = "very-high-speed"; /* in modules/hal/stm32/dts/st/f4/stm32f429iitx-pinctrl.dtsi:1505 */
				phandle = < 0x23 >;            /* in zephyr/boards/iar/stm32f429ii_aca/stm32f429ii_aca.dts:210 */
			};

			/* node '/soc/pin-controller@40020000/fmc_sdnras_pf11' defined in modules/hal/stm32/dts/st/f4/stm32f429iitx-pinctrl.dtsi:1508 */
			fmc_sdnras_pf11: fmc_sdnras_pf11 {
				pinmux = < 0xb6c >;            /* in modules/hal/stm32/dts/st/f4/stm32f429iitx-pinctrl.dtsi:1509 */
				bias-pull-up;                  /* in modules/hal/stm32/dts/st/f4/stm32f429iitx-pinctrl.dtsi:1510 */
				slew-rate = "very-high-speed"; /* in modules/hal/stm32/dts/st/f4/stm32f429iitx-pinctrl.dtsi:1511 */
				phandle = < 0x1c >;            /* in zephyr/boards/iar/stm32f429ii_aca/stm32f429ii_aca.dts:210 */
			};

			/* node '/soc/pin-controller@40020000/fmc_a6_pf12' defined in modules/hal/stm32/dts/st/f4/stm32f429iitx-pinctrl.dtsi:1514 */
			fmc_a6_pf12: fmc_a6_pf12 {
				pinmux = < 0xb8c >;            /* in modules/hal/stm32/dts/st/f4/stm32f429iitx-pinctrl.dtsi:1515 */
				bias-pull-up;                  /* in modules/hal/stm32/dts/st/f4/stm32f429iitx-pinctrl.dtsi:1516 */
				slew-rate = "very-high-speed"; /* in modules/hal/stm32/dts/st/f4/stm32f429iitx-pinctrl.dtsi:1517 */
				phandle = < 0x24 >;            /* in zephyr/boards/iar/stm32f429ii_aca/stm32f429ii_aca.dts:210 */
			};

			/* node '/soc/pin-controller@40020000/fmc_a7_pf13' defined in modules/hal/stm32/dts/st/f4/stm32f429iitx-pinctrl.dtsi:1520 */
			fmc_a7_pf13: fmc_a7_pf13 {
				pinmux = < 0xbac >;            /* in modules/hal/stm32/dts/st/f4/stm32f429iitx-pinctrl.dtsi:1521 */
				bias-pull-up;                  /* in modules/hal/stm32/dts/st/f4/stm32f429iitx-pinctrl.dtsi:1522 */
				slew-rate = "very-high-speed"; /* in modules/hal/stm32/dts/st/f4/stm32f429iitx-pinctrl.dtsi:1523 */
				phandle = < 0x25 >;            /* in zephyr/boards/iar/stm32f429ii_aca/stm32f429ii_aca.dts:210 */
			};

			/* node '/soc/pin-controller@40020000/fmc_a8_pf14' defined in modules/hal/stm32/dts/st/f4/stm32f429iitx-pinctrl.dtsi:1526 */
			fmc_a8_pf14: fmc_a8_pf14 {
				pinmux = < 0xbcc >;            /* in modules/hal/stm32/dts/st/f4/stm32f429iitx-pinctrl.dtsi:1527 */
				bias-pull-up;                  /* in modules/hal/stm32/dts/st/f4/stm32f429iitx-pinctrl.dtsi:1528 */
				slew-rate = "very-high-speed"; /* in modules/hal/stm32/dts/st/f4/stm32f429iitx-pinctrl.dtsi:1529 */
				phandle = < 0x26 >;            /* in zephyr/boards/iar/stm32f429ii_aca/stm32f429ii_aca.dts:210 */
			};

			/* node '/soc/pin-controller@40020000/fmc_a9_pf15' defined in modules/hal/stm32/dts/st/f4/stm32f429iitx-pinctrl.dtsi:1532 */
			fmc_a9_pf15: fmc_a9_pf15 {
				pinmux = < 0xbec >;            /* in modules/hal/stm32/dts/st/f4/stm32f429iitx-pinctrl.dtsi:1533 */
				bias-pull-up;                  /* in modules/hal/stm32/dts/st/f4/stm32f429iitx-pinctrl.dtsi:1534 */
				slew-rate = "very-high-speed"; /* in modules/hal/stm32/dts/st/f4/stm32f429iitx-pinctrl.dtsi:1535 */
				phandle = < 0x27 >;            /* in zephyr/boards/iar/stm32f429ii_aca/stm32f429ii_aca.dts:210 */
			};

			/* node '/soc/pin-controller@40020000/fmc_a10_pg0' defined in modules/hal/stm32/dts/st/f4/stm32f429iitx-pinctrl.dtsi:1538 */
			fmc_a10_pg0: fmc_a10_pg0 {
				pinmux = < 0xc0c >;            /* in modules/hal/stm32/dts/st/f4/stm32f429iitx-pinctrl.dtsi:1539 */
				bias-pull-up;                  /* in modules/hal/stm32/dts/st/f4/stm32f429iitx-pinctrl.dtsi:1540 */
				slew-rate = "very-high-speed"; /* in modules/hal/stm32/dts/st/f4/stm32f429iitx-pinctrl.dtsi:1541 */
				phandle = < 0x28 >;            /* in zephyr/boards/iar/stm32f429ii_aca/stm32f429ii_aca.dts:210 */
			};

			/* node '/soc/pin-controller@40020000/fmc_a11_pg1' defined in modules/hal/stm32/dts/st/f4/stm32f429iitx-pinctrl.dtsi:1544 */
			fmc_a11_pg1: fmc_a11_pg1 {
				pinmux = < 0xc2c >;            /* in modules/hal/stm32/dts/st/f4/stm32f429iitx-pinctrl.dtsi:1545 */
				bias-pull-up;                  /* in modules/hal/stm32/dts/st/f4/stm32f429iitx-pinctrl.dtsi:1546 */
				slew-rate = "very-high-speed"; /* in modules/hal/stm32/dts/st/f4/stm32f429iitx-pinctrl.dtsi:1547 */
				phandle = < 0x29 >;            /* in zephyr/boards/iar/stm32f429ii_aca/stm32f429ii_aca.dts:210 */
			};

			/* node '/soc/pin-controller@40020000/fmc_a12_pg2' defined in modules/hal/stm32/dts/st/f4/stm32f429iitx-pinctrl.dtsi:1550 */
			fmc_a12_pg2: fmc_a12_pg2 {
				pinmux = < 0xc4c >;            /* in modules/hal/stm32/dts/st/f4/stm32f429iitx-pinctrl.dtsi:1551 */
				bias-pull-up;                  /* in modules/hal/stm32/dts/st/f4/stm32f429iitx-pinctrl.dtsi:1552 */
				slew-rate = "very-high-speed"; /* in modules/hal/stm32/dts/st/f4/stm32f429iitx-pinctrl.dtsi:1553 */
				phandle = < 0x2a >;            /* in zephyr/boards/iar/stm32f429ii_aca/stm32f429ii_aca.dts:210 */
			};

			/* node '/soc/pin-controller@40020000/fmc_a13_pg3' defined in modules/hal/stm32/dts/st/f4/stm32f429iitx-pinctrl.dtsi:1556 */
			fmc_a13_pg3: fmc_a13_pg3 {
				pinmux = < 0xc6c >;            /* in modules/hal/stm32/dts/st/f4/stm32f429iitx-pinctrl.dtsi:1557 */
				bias-pull-up;                  /* in modules/hal/stm32/dts/st/f4/stm32f429iitx-pinctrl.dtsi:1558 */
				slew-rate = "very-high-speed"; /* in modules/hal/stm32/dts/st/f4/stm32f429iitx-pinctrl.dtsi:1559 */
				phandle = < 0x2b >;            /* in zephyr/boards/iar/stm32f429ii_aca/stm32f429ii_aca.dts:210 */
			};

			/* node '/soc/pin-controller@40020000/fmc_a14_pg4' defined in modules/hal/stm32/dts/st/f4/stm32f429iitx-pinctrl.dtsi:1562 */
			fmc_a14_pg4: fmc_a14_pg4 {
				pinmux = < 0xc8c >;            /* in modules/hal/stm32/dts/st/f4/stm32f429iitx-pinctrl.dtsi:1563 */
				bias-pull-up;                  /* in modules/hal/stm32/dts/st/f4/stm32f429iitx-pinctrl.dtsi:1564 */
				slew-rate = "very-high-speed"; /* in modules/hal/stm32/dts/st/f4/stm32f429iitx-pinctrl.dtsi:1565 */
				phandle = < 0x2c >;            /* in zephyr/boards/iar/stm32f429ii_aca/stm32f429ii_aca.dts:210 */
			};

			/* node '/soc/pin-controller@40020000/fmc_a15_pg5' defined in modules/hal/stm32/dts/st/f4/stm32f429iitx-pinctrl.dtsi:1568 */
			fmc_a15_pg5: fmc_a15_pg5 {
				pinmux = < 0xcac >;            /* in modules/hal/stm32/dts/st/f4/stm32f429iitx-pinctrl.dtsi:1569 */
				bias-pull-up;                  /* in modules/hal/stm32/dts/st/f4/stm32f429iitx-pinctrl.dtsi:1570 */
				slew-rate = "very-high-speed"; /* in modules/hal/stm32/dts/st/f4/stm32f429iitx-pinctrl.dtsi:1571 */
				phandle = < 0x2d >;            /* in zephyr/boards/iar/stm32f429ii_aca/stm32f429ii_aca.dts:210 */
			};

			/* node '/soc/pin-controller@40020000/fmc_sdclk_pg8' defined in modules/hal/stm32/dts/st/f4/stm32f429iitx-pinctrl.dtsi:1574 */
			fmc_sdclk_pg8: fmc_sdclk_pg8 {
				pinmux = < 0xd0c >;            /* in modules/hal/stm32/dts/st/f4/stm32f429iitx-pinctrl.dtsi:1575 */
				bias-pull-up;                  /* in modules/hal/stm32/dts/st/f4/stm32f429iitx-pinctrl.dtsi:1576 */
				slew-rate = "very-high-speed"; /* in modules/hal/stm32/dts/st/f4/stm32f429iitx-pinctrl.dtsi:1577 */
				phandle = < 0x18 >;            /* in zephyr/boards/iar/stm32f429ii_aca/stm32f429ii_aca.dts:210 */
			};

			/* node '/soc/pin-controller@40020000/fmc_sdncas_pg15' defined in modules/hal/stm32/dts/st/f4/stm32f429iitx-pinctrl.dtsi:1610 */
			fmc_sdncas_pg15: fmc_sdncas_pg15 {
				pinmux = < 0xdec >;            /* in modules/hal/stm32/dts/st/f4/stm32f429iitx-pinctrl.dtsi:1611 */
				bias-pull-up;                  /* in modules/hal/stm32/dts/st/f4/stm32f429iitx-pinctrl.dtsi:1612 */
				slew-rate = "very-high-speed"; /* in modules/hal/stm32/dts/st/f4/stm32f429iitx-pinctrl.dtsi:1613 */
				phandle = < 0x1d >;            /* in zephyr/boards/iar/stm32f429ii_aca/stm32f429ii_aca.dts:210 */
			};

			/* node '/soc/pin-controller@40020000/i2c1_scl_pb8' defined in modules/hal/stm32/dts/st/f4/stm32f429iitx-pinctrl.dtsi:1762 */
			i2c1_scl_pb8: i2c1_scl_pb8 {
				pinmux = < 0x304 >; /* in modules/hal/stm32/dts/st/f4/stm32f429iitx-pinctrl.dtsi:1763 */
				bias-pull-up;       /* in modules/hal/stm32/dts/st/f4/stm32f429iitx-pinctrl.dtsi:1764 */
				drive-open-drain;   /* in modules/hal/stm32/dts/st/f4/stm32f429iitx-pinctrl.dtsi:1765 */
				phandle = < 0x5 >;  /* in zephyr/boards/iar/stm32f429ii_aca/stm32f429ii_aca.dts:187 */
			};

			/* node '/soc/pin-controller@40020000/i2c2_scl_ph4' defined in modules/hal/stm32/dts/st/f4/stm32f429iitx-pinctrl.dtsi:1780 */
			i2c2_scl_ph4: i2c2_scl_ph4 {
				pinmux = < 0xe84 >; /* in modules/hal/stm32/dts/st/f4/stm32f429iitx-pinctrl.dtsi:1781 */
				bias-pull-up;       /* in modules/hal/stm32/dts/st/f4/stm32f429iitx-pinctrl.dtsi:1782 */
				drive-open-drain;   /* in modules/hal/stm32/dts/st/f4/stm32f429iitx-pinctrl.dtsi:1783 */
				phandle = < 0x7 >;  /* in zephyr/boards/iar/stm32f429ii_aca/stm32f429ii_aca.dts:194 */
			};

			/* node '/soc/pin-controller@40020000/i2c1_sda_pb7' defined in modules/hal/stm32/dts/st/f4/stm32f429iitx-pinctrl.dtsi:1800 */
			i2c1_sda_pb7: i2c1_sda_pb7 {
				pinmux = < 0x2e4 >; /* in modules/hal/stm32/dts/st/f4/stm32f429iitx-pinctrl.dtsi:1801 */
				bias-pull-up;       /* in modules/hal/stm32/dts/st/f4/stm32f429iitx-pinctrl.dtsi:1802 */
				drive-open-drain;   /* in modules/hal/stm32/dts/st/f4/stm32f429iitx-pinctrl.dtsi:1803 */
				phandle = < 0x6 >;  /* in zephyr/boards/iar/stm32f429ii_aca/stm32f429ii_aca.dts:187 */
			};

			/* node '/soc/pin-controller@40020000/i2c2_sda_ph5' defined in modules/hal/stm32/dts/st/f4/stm32f429iitx-pinctrl.dtsi:1824 */
			i2c2_sda_ph5: i2c2_sda_ph5 {
				pinmux = < 0xea4 >; /* in modules/hal/stm32/dts/st/f4/stm32f429iitx-pinctrl.dtsi:1825 */
				bias-pull-up;       /* in modules/hal/stm32/dts/st/f4/stm32f429iitx-pinctrl.dtsi:1826 */
				drive-open-drain;   /* in modules/hal/stm32/dts/st/f4/stm32f429iitx-pinctrl.dtsi:1827 */
				phandle = < 0x8 >;  /* in zephyr/boards/iar/stm32f429ii_aca/stm32f429ii_aca.dts:194 */
			};

			/* node '/soc/pin-controller@40020000/spi5_miso_pf8' defined in modules/hal/stm32/dts/st/f4/stm32f429iitx-pinctrl.dtsi:2365 */
			spi5_miso_pf8: spi5_miso_pf8 {
				pinmux = < 0xb05 >; /* in modules/hal/stm32/dts/st/f4/stm32f429iitx-pinctrl.dtsi:2366 */
				bias-pull-down;     /* in modules/hal/stm32/dts/st/f4/stm32f429iitx-pinctrl.dtsi:2367 */
				phandle = < 0x13 >; /* in zephyr/boards/iar/stm32f429ii_aca/stm32f429ii_aca.dts:201 */
			};

			/* node '/soc/pin-controller@40020000/spi5_mosi_pf9' defined in modules/hal/stm32/dts/st/f4/stm32f429iitx-pinctrl.dtsi:2432 */
			spi5_mosi_pf9: spi5_mosi_pf9 {
				pinmux = < 0xb25 >; /* in modules/hal/stm32/dts/st/f4/stm32f429iitx-pinctrl.dtsi:2433 */
				bias-pull-down;     /* in modules/hal/stm32/dts/st/f4/stm32f429iitx-pinctrl.dtsi:2434 */
				phandle = < 0x14 >; /* in zephyr/boards/iar/stm32f429ii_aca/stm32f429ii_aca.dts:201 */
			};

			/* node '/soc/pin-controller@40020000/spi5_nss_pf6' defined in modules/hal/stm32/dts/st/f4/stm32f429iitx-pinctrl.dtsi:2494 */
			spi5_nss_pf6: spi5_nss_pf6 {
				pinmux = < 0xac5 >; /* in modules/hal/stm32/dts/st/f4/stm32f429iitx-pinctrl.dtsi:2495 */
				bias-pull-up;       /* in modules/hal/stm32/dts/st/f4/stm32f429iitx-pinctrl.dtsi:2496 */
				phandle = < 0x11 >; /* in zephyr/boards/iar/stm32f429ii_aca/stm32f429ii_aca.dts:201 */
			};

			/* node '/soc/pin-controller@40020000/spi5_sck_pf7' defined in modules/hal/stm32/dts/st/f4/stm32f429iitx-pinctrl.dtsi:2571 */
			spi5_sck_pf7: spi5_sck_pf7 {
				pinmux = < 0xae5 >;            /* in modules/hal/stm32/dts/st/f4/stm32f429iitx-pinctrl.dtsi:2572 */
				bias-pull-down;                /* in modules/hal/stm32/dts/st/f4/stm32f429iitx-pinctrl.dtsi:2573 */
				slew-rate = "very-high-speed"; /* in modules/hal/stm32/dts/st/f4/stm32f429iitx-pinctrl.dtsi:2574 */
				phandle = < 0x12 >;            /* in zephyr/boards/iar/stm32f429ii_aca/stm32f429ii_aca.dts:201 */
			};

			/* node '/soc/pin-controller@40020000/usb_otg_hs_id_pb12' defined in modules/hal/stm32/dts/st/f4/stm32f429iitx-pinctrl.dtsi:3194 */
			usb_otg_hs_id_pb12: usb_otg_hs_id_pb12 {
				pinmux = < 0x38c >; /* in modules/hal/stm32/dts/st/f4/stm32f429iitx-pinctrl.dtsi:3195 */
				phandle = < 0xe >;  /* in zephyr/boards/iar/stm32f429ii_aca/stm32f429ii_aca.dts:273 */
			};

			/* node '/soc/pin-controller@40020000/usb_otg_hs_dm_pb14' defined in modules/hal/stm32/dts/st/f4/stm32f429iitx-pinctrl.dtsi:3202 */
			usb_otg_hs_dm_pb14: usb_otg_hs_dm_pb14 {
				pinmux = < 0x3cc >; /* in modules/hal/stm32/dts/st/f4/stm32f429iitx-pinctrl.dtsi:3203 */
				phandle = < 0xc >;  /* in zephyr/boards/iar/stm32f429ii_aca/stm32f429ii_aca.dts:273 */
			};

			/* node '/soc/pin-controller@40020000/usb_otg_hs_dp_pb15' defined in modules/hal/stm32/dts/st/f4/stm32f429iitx-pinctrl.dtsi:3206 */
			usb_otg_hs_dp_pb15: usb_otg_hs_dp_pb15 {
				pinmux = < 0x3ec >; /* in modules/hal/stm32/dts/st/f4/stm32f429iitx-pinctrl.dtsi:3207 */
				phandle = < 0xd >;  /* in zephyr/boards/iar/stm32f429ii_aca/stm32f429ii_aca.dts:273 */
			};
		};

		/* node '/soc/watchdog@40003000' defined in zephyr/dts/arm/st/f4/stm32f4.dtsi:227 */
		iwdg: watchdog@40003000 {
			compatible = "st,stm32-watchdog"; /* in zephyr/dts/arm/st/f4/stm32f4.dtsi:228 */
			reg = < 0x40003000 0x400 >;       /* in zephyr/dts/arm/st/f4/stm32f4.dtsi:229 */
			status = "disabled";              /* in zephyr/dts/arm/st/f4/stm32f4.dtsi:230 */
		};

		/* node '/soc/watchdog@40002c00' defined in zephyr/dts/arm/st/f4/stm32f4.dtsi:233 */
		wwdg: watchdog@40002c00 {
			compatible = "st,stm32-window-watchdog"; /* in zephyr/dts/arm/st/f4/stm32f4.dtsi:234 */
			reg = < 0x40002c00 0x400 >;              /* in zephyr/dts/arm/st/f4/stm32f4.dtsi:235 */
			clocks = < &rcc 0x40 0x800 >;            /* in zephyr/dts/arm/st/f4/stm32f4.dtsi:236 */
			interrupts = < 0x0 0x7 >;                /* in zephyr/dts/arm/st/f4/stm32f4.dtsi:237 */
			status = "disabled";                     /* in zephyr/dts/arm/st/f4/stm32f4.dtsi:238 */
		};

		/* node '/soc/serial@40011000' defined in zephyr/dts/arm/st/f4/stm32f4.dtsi:241 */
		usart1: serial@40011000 {
			compatible = "st,stm32-usart",
			             "st,stm32-uart";  /* in zephyr/dts/arm/st/f4/stm32f4.dtsi:242 */
			reg = < 0x40011000 0x400 >;    /* in zephyr/dts/arm/st/f4/stm32f4.dtsi:243 */
			clocks = < &rcc 0x44 0x10 >;   /* in zephyr/dts/arm/st/f4/stm32f4.dtsi:244 */
			resets = < &rctl 0x484 >;      /* in zephyr/dts/arm/st/f4/stm32f4.dtsi:245 */
			interrupts = < 0x25 0x0 >;     /* in zephyr/dts/arm/st/f4/stm32f4.dtsi:246 */
			status = "disabled";           /* in zephyr/dts/arm/st/f4/stm32f4.dtsi:247 */
		};

		/* node '/soc/serial@40004400' defined in zephyr/dts/arm/st/f4/stm32f4.dtsi:250 */
		usart2: serial@40004400 {
			compatible = "st,stm32-usart",
			             "st,stm32-uart";   /* in zephyr/dts/arm/st/f4/stm32f4.dtsi:251 */
			reg = < 0x40004400 0x400 >;     /* in zephyr/dts/arm/st/f4/stm32f4.dtsi:252 */
			clocks = < &rcc 0x40 0x20000 >; /* in zephyr/dts/arm/st/f4/stm32f4.dtsi:253 */
			resets = < &rctl 0x411 >;       /* in zephyr/dts/arm/st/f4/stm32f4.dtsi:254 */
			interrupts = < 0x26 0x0 >;      /* in zephyr/dts/arm/st/f4/stm32f4.dtsi:255 */
			status = "disabled";            /* in zephyr/dts/arm/st/f4/stm32f4.dtsi:256 */
		};

		/* node '/soc/serial@40011400' defined in zephyr/dts/arm/st/f4/stm32f4.dtsi:259 */
		usart6: serial@40011400 {
			compatible = "st,stm32-usart",
			             "st,stm32-uart";  /* in zephyr/dts/arm/st/f4/stm32f4.dtsi:260 */
			reg = < 0x40011400 0x400 >;    /* in zephyr/dts/arm/st/f4/stm32f4.dtsi:261 */
			clocks = < &rcc 0x44 0x20 >;   /* in zephyr/dts/arm/st/f4/stm32f4.dtsi:262 */
			resets = < &rctl 0x485 >;      /* in zephyr/dts/arm/st/f4/stm32f4.dtsi:263 */
			interrupts = < 0x47 0x0 >;     /* in zephyr/dts/arm/st/f4/stm32f4.dtsi:264 */
			status = "disabled";           /* in zephyr/dts/arm/st/f4/stm32f4.dtsi:265 */
		};

		/* node '/soc/i2c@40005400' defined in zephyr/dts/arm/st/f4/stm32f4.dtsi:268 */
		i2c1: i2c@40005400 {
			compatible = "st,stm32-i2c-v1";              /* in zephyr/dts/arm/st/f4/stm32f4.dtsi:269 */
			#address-cells = < 0x1 >;                    /* in zephyr/dts/arm/st/f4/stm32f4.dtsi:271 */
			#size-cells = < 0x0 >;                       /* in zephyr/dts/arm/st/f4/stm32f4.dtsi:272 */
			reg = < 0x40005400 0x400 >;                  /* in zephyr/dts/arm/st/f4/stm32f4.dtsi:273 */
			clocks = < &rcc 0x40 0x200000 >;             /* in zephyr/dts/arm/st/f4/stm32f4.dtsi:274 */
			interrupts = < 0x1f 0x0 >,
			             < 0x20 0x0 >;                   /* in zephyr/dts/arm/st/f4/stm32f4.dtsi:275 */
			interrupt-names = "event",
			                  "error";                   /* in zephyr/dts/arm/st/f4/stm32f4.dtsi:276 */
			pinctrl-0 = < &i2c1_scl_pb8 &i2c1_sda_pb7 >; /* in zephyr/boards/iar/stm32f429ii_aca/stm32f429ii_aca.dts:187 */
			pinctrl-names = "default";                   /* in zephyr/boards/iar/stm32f429ii_aca/stm32f429ii_aca.dts:188 */
			status = "okay";                             /* in zephyr/boards/iar/stm32f429ii_aca/stm32f429ii_aca.dts:189 */
			clock-frequency = < 0x61a80 >;               /* in zephyr/boards/iar/stm32f429ii_aca/stm32f429ii_aca.dts:190 */
			phandle = < 0x43 >;                          /* in zephyr/dts/arm/st/f4/stm32f4.dtsi:654 */
		};

		/* node '/soc/i2c@40005800' defined in zephyr/dts/arm/st/f4/stm32f4.dtsi:280 */
		i2c2: i2c@40005800 {
			compatible = "st,stm32-i2c-v1";              /* in zephyr/dts/arm/st/f4/stm32f4.dtsi:281 */
			#address-cells = < 0x1 >;                    /* in zephyr/dts/arm/st/f4/stm32f4.dtsi:283 */
			#size-cells = < 0x0 >;                       /* in zephyr/dts/arm/st/f4/stm32f4.dtsi:284 */
			reg = < 0x40005800 0x400 >;                  /* in zephyr/dts/arm/st/f4/stm32f4.dtsi:285 */
			clocks = < &rcc 0x40 0x400000 >;             /* in zephyr/dts/arm/st/f4/stm32f4.dtsi:286 */
			interrupts = < 0x21 0x0 >,
			             < 0x22 0x0 >;                   /* in zephyr/dts/arm/st/f4/stm32f4.dtsi:287 */
			interrupt-names = "event",
			                  "error";                   /* in zephyr/dts/arm/st/f4/stm32f4.dtsi:288 */
			pinctrl-0 = < &i2c2_scl_ph4 &i2c2_sda_ph5 >; /* in zephyr/boards/iar/stm32f429ii_aca/stm32f429ii_aca.dts:194 */
			pinctrl-names = "default";                   /* in zephyr/boards/iar/stm32f429ii_aca/stm32f429ii_aca.dts:195 */
			status = "okay";                             /* in zephyr/boards/iar/stm32f429ii_aca/stm32f429ii_aca.dts:196 */
			clock-frequency = < 0x61a80 >;               /* in zephyr/boards/iar/stm32f429ii_aca/stm32f429ii_aca.dts:197 */
			phandle = < 0x44 >;                          /* in zephyr/dts/arm/st/f4/stm32f4.dtsi:662 */
		};

		/* node '/soc/i2c@40005c00' defined in zephyr/dts/arm/st/f4/stm32f4.dtsi:292 */
		i2c3: i2c@40005c00 {
			compatible = "st,stm32-i2c-v1";  /* in zephyr/dts/arm/st/f4/stm32f4.dtsi:293 */
			clock-frequency = < 0x186a0 >;   /* in zephyr/dts/arm/st/f4/stm32f4.dtsi:294 */
			#address-cells = < 0x1 >;        /* in zephyr/dts/arm/st/f4/stm32f4.dtsi:295 */
			#size-cells = < 0x0 >;           /* in zephyr/dts/arm/st/f4/stm32f4.dtsi:296 */
			reg = < 0x40005c00 0x400 >;      /* in zephyr/dts/arm/st/f4/stm32f4.dtsi:297 */
			clocks = < &rcc 0x40 0x800000 >; /* in zephyr/dts/arm/st/f4/stm32f4.dtsi:298 */
			interrupts = < 0x48 0x0 >,
			             < 0x49 0x0 >;       /* in zephyr/dts/arm/st/f4/stm32f4.dtsi:299 */
			interrupt-names = "event",
			                  "error";       /* in zephyr/dts/arm/st/f4/stm32f4.dtsi:300 */
			status = "disabled";             /* in zephyr/dts/arm/st/f4/stm32f4.dtsi:301 */
			phandle = < 0x45 >;              /* in zephyr/dts/arm/st/f4/stm32f4.dtsi:670 */
		};

		/* node '/soc/spi@40013000' defined in zephyr/dts/arm/st/f4/stm32f4.dtsi:304 */
		spi1: spi@40013000 {
			compatible = "st,stm32-spi";   /* in zephyr/dts/arm/st/f4/stm32f4.dtsi:305 */
			#address-cells = < 0x1 >;      /* in zephyr/dts/arm/st/f4/stm32f4.dtsi:306 */
			#size-cells = < 0x0 >;         /* in zephyr/dts/arm/st/f4/stm32f4.dtsi:307 */
			reg = < 0x40013000 0x400 >;    /* in zephyr/dts/arm/st/f4/stm32f4.dtsi:308 */
			clocks = < &rcc 0x44 0x1000 >; /* in zephyr/dts/arm/st/f4/stm32f4.dtsi:309 */
			interrupts = < 0x23 0x5 >;     /* in zephyr/dts/arm/st/f4/stm32f4.dtsi:310 */
			status = "disabled";           /* in zephyr/dts/arm/st/f4/stm32f4.dtsi:311 */
		};

		/* node '/soc/usb@50000000' defined in zephyr/dts/arm/st/f4/stm32f4.dtsi:314 */
		usbotg_fs: usb@50000000 {
			compatible = "st,stm32-otgfs"; /* in zephyr/dts/arm/st/f4/stm32f4.dtsi:315 */
			reg = < 0x50000000 0x40000 >;  /* in zephyr/dts/arm/st/f4/stm32f4.dtsi:316 */
			interrupts = < 0x43 0x0 >;     /* in zephyr/dts/arm/st/f4/stm32f4.dtsi:317 */
			interrupt-names = "otgfs";     /* in zephyr/dts/arm/st/f4/stm32f4.dtsi:318 */
			num-bidir-endpoints = < 0x4 >; /* in zephyr/dts/arm/st/f4/stm32f4.dtsi:319 */
			ram-size = < 0x500 >;          /* in zephyr/dts/arm/st/f4/stm32f4.dtsi:320 */
			maximum-speed = "full-speed";  /* in zephyr/dts/arm/st/f4/stm32f4.dtsi:321 */
			phys = < &otgfs_phy >;         /* in zephyr/dts/arm/st/f4/stm32f4.dtsi:322 */
			clocks = < &rcc 0x34 0x80 >,
			         < &rcc 0x7 0xff >;    /* in zephyr/dts/arm/st/f4/stm32f4.dtsi:323 */
			status = "disabled";           /* in zephyr/dts/arm/st/f4/stm32f4.dtsi:325 */
		};

		/* node '/soc/timers@40010000' defined in zephyr/dts/arm/st/f4/stm32f4.dtsi:328 */
		timers1: timers@40010000 {
			compatible = "st,stm32-timers"; /* in zephyr/dts/arm/st/f4/stm32f4.dtsi:329 */
			reg = < 0x40010000 0x400 >;     /* in zephyr/dts/arm/st/f4/stm32f4.dtsi:330 */
			clocks = < &rcc 0x44 0x1 >,
			         < &rcc 0xd 0xff >;     /* in zephyr/dts/arm/st/f4/stm32f4.dtsi:331 */
			resets = < &rctl 0x480 >;       /* in zephyr/dts/arm/st/f4/stm32f4.dtsi:333 */
			interrupts = < 0x18 0x0 >,
			             < 0x19 0x0 >,
			             < 0x1a 0x0 >,
			             < 0x1b 0x0 >;      /* in zephyr/dts/arm/st/f4/stm32f4.dtsi:334 */
			interrupt-names = "brk",
			                  "up",
			                  "trgcom",
			                  "cc";         /* in zephyr/dts/arm/st/f4/stm32f4.dtsi:335 */
			st,prescaler = < 0x0 >;         /* in zephyr/dts/arm/st/f4/stm32f4.dtsi:336 */
			status = "disabled";            /* in zephyr/dts/arm/st/f4/stm32f4.dtsi:337 */

			/* node '/soc/timers@40010000/pwm' defined in zephyr/dts/arm/st/f4/stm32f4.dtsi:339 */
			pwm {
				compatible = "st,stm32-pwm"; /* in zephyr/dts/arm/st/f4/stm32f4.dtsi:340 */
				status = "disabled";         /* in zephyr/dts/arm/st/f4/stm32f4.dtsi:341 */
				#pwm-cells = < 0x3 >;        /* in zephyr/dts/arm/st/f4/stm32f4.dtsi:342 */
			};

			/* node '/soc/timers@40010000/qdec' defined in zephyr/dts/arm/st/f4/stm32f4.dtsi:345 */
			qdec {
				compatible = "st,stm32-qdec";    /* in zephyr/dts/arm/st/f4/stm32f4.dtsi:346 */
				st,input-filter-level = < 0x0 >; /* in zephyr/dts/arm/st/f4/stm32f4.dtsi:347 */
				status = "disabled";             /* in zephyr/dts/arm/st/f4/stm32f4.dtsi:348 */
			};
		};

		/* node '/soc/timers@40000000' defined in zephyr/dts/arm/st/f4/stm32f4.dtsi:352 */
		timers2: timers@40000000 {
			compatible = "st,stm32-timers"; /* in zephyr/dts/arm/st/f4/stm32f4.dtsi:353 */
			reg = < 0x40000000 0x400 >;     /* in zephyr/dts/arm/st/f4/stm32f4.dtsi:354 */
			clocks = < &rcc 0x40 0x1 >,
			         < &rcc 0xc 0xff >;     /* in zephyr/dts/arm/st/f4/stm32f4.dtsi:355 */
			resets = < &rctl 0x400 >;       /* in zephyr/dts/arm/st/f4/stm32f4.dtsi:357 */
			interrupts = < 0x1c 0x0 >;      /* in zephyr/dts/arm/st/f4/stm32f4.dtsi:358 */
			interrupt-names = "global";     /* in zephyr/dts/arm/st/f4/stm32f4.dtsi:359 */
			st,prescaler = < 0x0 >;         /* in zephyr/dts/arm/st/f4/stm32f4.dtsi:360 */
			status = "disabled";            /* in zephyr/dts/arm/st/f4/stm32f4.dtsi:361 */

			/* node '/soc/timers@40000000/pwm' defined in zephyr/dts/arm/st/f4/stm32f4.dtsi:363 */
			pwm {
				compatible = "st,stm32-pwm"; /* in zephyr/dts/arm/st/f4/stm32f4.dtsi:364 */
				status = "disabled";         /* in zephyr/dts/arm/st/f4/stm32f4.dtsi:365 */
				#pwm-cells = < 0x3 >;        /* in zephyr/dts/arm/st/f4/stm32f4.dtsi:366 */
			};

			/* node '/soc/timers@40000000/counter' defined in zephyr/dts/arm/st/f4/stm32f4.dtsi:369 */
			counter {
				compatible = "st,stm32-counter"; /* in zephyr/dts/arm/st/f4/stm32f4.dtsi:370 */
				status = "disabled";             /* in zephyr/dts/arm/st/f4/stm32f4.dtsi:371 */
			};

			/* node '/soc/timers@40000000/qdec' defined in zephyr/dts/arm/st/f4/stm32f4.dtsi:374 */
			qdec {
				compatible = "st,stm32-qdec";    /* in zephyr/dts/arm/st/f4/stm32f4.dtsi:375 */
				st,input-filter-level = < 0x0 >; /* in zephyr/dts/arm/st/f4/stm32f4.dtsi:376 */
				status = "disabled";             /* in zephyr/dts/arm/st/f4/stm32f4.dtsi:377 */
			};
		};

		/* node '/soc/timers@40000400' defined in zephyr/dts/arm/st/f4/stm32f4.dtsi:381 */
		timers3: timers@40000400 {
			compatible = "st,stm32-timers"; /* in zephyr/dts/arm/st/f4/stm32f4.dtsi:382 */
			reg = < 0x40000400 0x400 >;     /* in zephyr/dts/arm/st/f4/stm32f4.dtsi:383 */
			clocks = < &rcc 0x40 0x2 >,
			         < &rcc 0xc 0xff >;     /* in zephyr/dts/arm/st/f4/stm32f4.dtsi:384 */
			resets = < &rctl 0x401 >;       /* in zephyr/dts/arm/st/f4/stm32f4.dtsi:386 */
			interrupts = < 0x1d 0x0 >;      /* in zephyr/dts/arm/st/f4/stm32f4.dtsi:387 */
			interrupt-names = "global";     /* in zephyr/dts/arm/st/f4/stm32f4.dtsi:388 */
			st,prescaler = < 0x0 >;         /* in zephyr/dts/arm/st/f4/stm32f4.dtsi:389 */
			status = "disabled";            /* in zephyr/dts/arm/st/f4/stm32f4.dtsi:390 */

			/* node '/soc/timers@40000400/pwm' defined in zephyr/dts/arm/st/f4/stm32f4.dtsi:392 */
			pwm {
				compatible = "st,stm32-pwm"; /* in zephyr/dts/arm/st/f4/stm32f4.dtsi:393 */
				status = "disabled";         /* in zephyr/dts/arm/st/f4/stm32f4.dtsi:394 */
				#pwm-cells = < 0x3 >;        /* in zephyr/dts/arm/st/f4/stm32f4.dtsi:395 */
			};

			/* node '/soc/timers@40000400/counter' defined in zephyr/dts/arm/st/f4/stm32f4.dtsi:398 */
			counter {
				compatible = "st,stm32-counter"; /* in zephyr/dts/arm/st/f4/stm32f4.dtsi:399 */
				status = "disabled";             /* in zephyr/dts/arm/st/f4/stm32f4.dtsi:400 */
			};

			/* node '/soc/timers@40000400/qdec' defined in zephyr/dts/arm/st/f4/stm32f4.dtsi:403 */
			qdec {
				compatible = "st,stm32-qdec";    /* in zephyr/dts/arm/st/f4/stm32f4.dtsi:404 */
				st,input-filter-level = < 0x0 >; /* in zephyr/dts/arm/st/f4/stm32f4.dtsi:405 */
				status = "disabled";             /* in zephyr/dts/arm/st/f4/stm32f4.dtsi:406 */
			};
		};

		/* node '/soc/timers@40000800' defined in zephyr/dts/arm/st/f4/stm32f4.dtsi:410 */
		timers4: timers@40000800 {
			compatible = "st,stm32-timers"; /* in zephyr/dts/arm/st/f4/stm32f4.dtsi:411 */
			reg = < 0x40000800 0x400 >;     /* in zephyr/dts/arm/st/f4/stm32f4.dtsi:412 */
			clocks = < &rcc 0x40 0x4 >,
			         < &rcc 0xc 0xff >;     /* in zephyr/dts/arm/st/f4/stm32f4.dtsi:413 */
			resets = < &rctl 0x402 >;       /* in zephyr/dts/arm/st/f4/stm32f4.dtsi:415 */
			interrupts = < 0x1e 0x0 >;      /* in zephyr/dts/arm/st/f4/stm32f4.dtsi:416 */
			interrupt-names = "global";     /* in zephyr/dts/arm/st/f4/stm32f4.dtsi:417 */
			st,prescaler = < 0x0 >;         /* in zephyr/dts/arm/st/f4/stm32f4.dtsi:418 */
			status = "disabled";            /* in zephyr/dts/arm/st/f4/stm32f4.dtsi:419 */

			/* node '/soc/timers@40000800/pwm' defined in zephyr/dts/arm/st/f4/stm32f4.dtsi:421 */
			pwm {
				compatible = "st,stm32-pwm"; /* in zephyr/dts/arm/st/f4/stm32f4.dtsi:422 */
				status = "disabled";         /* in zephyr/dts/arm/st/f4/stm32f4.dtsi:423 */
				#pwm-cells = < 0x3 >;        /* in zephyr/dts/arm/st/f4/stm32f4.dtsi:424 */
			};

			/* node '/soc/timers@40000800/counter' defined in zephyr/dts/arm/st/f4/stm32f4.dtsi:427 */
			counter {
				compatible = "st,stm32-counter"; /* in zephyr/dts/arm/st/f4/stm32f4.dtsi:428 */
				status = "disabled";             /* in zephyr/dts/arm/st/f4/stm32f4.dtsi:429 */
			};

			/* node '/soc/timers@40000800/qdec' defined in zephyr/dts/arm/st/f4/stm32f4.dtsi:432 */
			qdec {
				compatible = "st,stm32-qdec";    /* in zephyr/dts/arm/st/f4/stm32f4.dtsi:433 */
				st,input-filter-level = < 0x0 >; /* in zephyr/dts/arm/st/f4/stm32f4.dtsi:434 */
				status = "disabled";             /* in zephyr/dts/arm/st/f4/stm32f4.dtsi:435 */
			};
		};

		/* node '/soc/timers@40000c00' defined in zephyr/dts/arm/st/f4/stm32f4.dtsi:439 */
		timers5: timers@40000c00 {
			compatible = "st,stm32-timers"; /* in zephyr/dts/arm/st/f4/stm32f4.dtsi:440 */
			reg = < 0x40000c00 0x400 >;     /* in zephyr/dts/arm/st/f4/stm32f4.dtsi:441 */
			clocks = < &rcc 0x40 0x8 >,
			         < &rcc 0xc 0xff >;     /* in zephyr/dts/arm/st/f4/stm32f4.dtsi:442 */
			resets = < &rctl 0x403 >;       /* in zephyr/dts/arm/st/f4/stm32f4.dtsi:444 */
			interrupts = < 0x32 0x0 >;      /* in zephyr/dts/arm/st/f4/stm32f4.dtsi:445 */
			interrupt-names = "global";     /* in zephyr/dts/arm/st/f4/stm32f4.dtsi:446 */
			st,prescaler = < 0x0 >;         /* in zephyr/dts/arm/st/f4/stm32f4.dtsi:447 */
			status = "disabled";            /* in zephyr/dts/arm/st/f4/stm32f4.dtsi:448 */

			/* node '/soc/timers@40000c00/pwm' defined in zephyr/dts/arm/st/f4/stm32f4.dtsi:450 */
			pwm {
				compatible = "st,stm32-pwm"; /* in zephyr/dts/arm/st/f4/stm32f4.dtsi:451 */
				status = "disabled";         /* in zephyr/dts/arm/st/f4/stm32f4.dtsi:452 */
				#pwm-cells = < 0x3 >;        /* in zephyr/dts/arm/st/f4/stm32f4.dtsi:453 */
			};

			/* node '/soc/timers@40000c00/counter' defined in zephyr/dts/arm/st/f4/stm32f4.dtsi:456 */
			counter {
				compatible = "st,stm32-counter"; /* in zephyr/dts/arm/st/f4/stm32f4.dtsi:457 */
				status = "disabled";             /* in zephyr/dts/arm/st/f4/stm32f4.dtsi:458 */
			};

			/* node '/soc/timers@40000c00/qdec' defined in zephyr/dts/arm/st/f4/stm32f4.dtsi:461 */
			qdec {
				compatible = "st,stm32-qdec";    /* in zephyr/dts/arm/st/f4/stm32f4.dtsi:462 */
				st,input-filter-level = < 0x0 >; /* in zephyr/dts/arm/st/f4/stm32f4.dtsi:463 */
				status = "disabled";             /* in zephyr/dts/arm/st/f4/stm32f4.dtsi:464 */
			};
		};

		/* node '/soc/timers@40014000' defined in zephyr/dts/arm/st/f4/stm32f4.dtsi:468 */
		timers9: timers@40014000 {
			compatible = "st,stm32-timers"; /* in zephyr/dts/arm/st/f4/stm32f4.dtsi:469 */
			reg = < 0x40014000 0x400 >;     /* in zephyr/dts/arm/st/f4/stm32f4.dtsi:470 */
			clocks = < &rcc 0x44 0x10000 >,
			         < &rcc 0xd 0xff >;     /* in zephyr/dts/arm/st/f4/stm32f4.dtsi:471 */
			resets = < &rctl 0x490 >;       /* in zephyr/dts/arm/st/f4/stm32f4.dtsi:473 */
			interrupts = < 0x18 0x0 >;      /* in zephyr/dts/arm/st/f4/stm32f4.dtsi:474 */
			interrupt-names = "global";     /* in zephyr/dts/arm/st/f4/stm32f4.dtsi:475 */
			st,prescaler = < 0x0 >;         /* in zephyr/dts/arm/st/f4/stm32f4.dtsi:476 */
			status = "disabled";            /* in zephyr/dts/arm/st/f4/stm32f4.dtsi:477 */

			/* node '/soc/timers@40014000/pwm' defined in zephyr/dts/arm/st/f4/stm32f4.dtsi:479 */
			pwm {
				compatible = "st,stm32-pwm"; /* in zephyr/dts/arm/st/f4/stm32f4.dtsi:480 */
				status = "disabled";         /* in zephyr/dts/arm/st/f4/stm32f4.dtsi:481 */
				#pwm-cells = < 0x3 >;        /* in zephyr/dts/arm/st/f4/stm32f4.dtsi:482 */
			};

			/* node '/soc/timers@40014000/counter' defined in zephyr/dts/arm/st/f4/stm32f4.dtsi:485 */
			counter {
				compatible = "st,stm32-counter"; /* in zephyr/dts/arm/st/f4/stm32f4.dtsi:486 */
				status = "disabled";             /* in zephyr/dts/arm/st/f4/stm32f4.dtsi:487 */
			};
		};

		/* node '/soc/timers@40014400' defined in zephyr/dts/arm/st/f4/stm32f4.dtsi:491 */
		timers10: timers@40014400 {
			compatible = "st,stm32-timers"; /* in zephyr/dts/arm/st/f4/stm32f4.dtsi:492 */
			reg = < 0x40014400 0x400 >;     /* in zephyr/dts/arm/st/f4/stm32f4.dtsi:493 */
			clocks = < &rcc 0x44 0x20000 >,
			         < &rcc 0xd 0xff >;     /* in zephyr/dts/arm/st/f4/stm32f4.dtsi:494 */
			resets = < &rctl 0x491 >;       /* in zephyr/dts/arm/st/f4/stm32f4.dtsi:496 */
			interrupts = < 0x19 0x0 >;      /* in zephyr/dts/arm/st/f4/stm32f4.dtsi:497 */
			interrupt-names = "global";     /* in zephyr/dts/arm/st/f4/stm32f4.dtsi:498 */
			st,prescaler = < 0x0 >;         /* in zephyr/dts/arm/st/f4/stm32f4.dtsi:499 */
			status = "disabled";            /* in zephyr/dts/arm/st/f4/stm32f4.dtsi:500 */

			/* node '/soc/timers@40014400/pwm' defined in zephyr/dts/arm/st/f4/stm32f4.dtsi:502 */
			pwm {
				compatible = "st,stm32-pwm"; /* in zephyr/dts/arm/st/f4/stm32f4.dtsi:503 */
				status = "disabled";         /* in zephyr/dts/arm/st/f4/stm32f4.dtsi:504 */
				#pwm-cells = < 0x3 >;        /* in zephyr/dts/arm/st/f4/stm32f4.dtsi:505 */
			};

			/* node '/soc/timers@40014400/counter' defined in zephyr/dts/arm/st/f4/stm32f4.dtsi:508 */
			counter {
				compatible = "st,stm32-counter"; /* in zephyr/dts/arm/st/f4/stm32f4.dtsi:509 */
				status = "disabled";             /* in zephyr/dts/arm/st/f4/stm32f4.dtsi:510 */
			};
		};

		/* node '/soc/timers@40014800' defined in zephyr/dts/arm/st/f4/stm32f4.dtsi:514 */
		timers11: timers@40014800 {
			compatible = "st,stm32-timers"; /* in zephyr/dts/arm/st/f4/stm32f4.dtsi:515 */
			reg = < 0x40014800 0x400 >;     /* in zephyr/dts/arm/st/f4/stm32f4.dtsi:516 */
			clocks = < &rcc 0x44 0x40000 >,
			         < &rcc 0xd 0xff >;     /* in zephyr/dts/arm/st/f4/stm32f4.dtsi:517 */
			resets = < &rctl 0x492 >;       /* in zephyr/dts/arm/st/f4/stm32f4.dtsi:519 */
			interrupts = < 0x1a 0x0 >;      /* in zephyr/dts/arm/st/f4/stm32f4.dtsi:520 */
			interrupt-names = "global";     /* in zephyr/dts/arm/st/f4/stm32f4.dtsi:521 */
			st,prescaler = < 0x0 >;         /* in zephyr/dts/arm/st/f4/stm32f4.dtsi:522 */
			status = "disabled";            /* in zephyr/dts/arm/st/f4/stm32f4.dtsi:523 */

			/* node '/soc/timers@40014800/pwm' defined in zephyr/dts/arm/st/f4/stm32f4.dtsi:525 */
			pwm {
				compatible = "st,stm32-pwm"; /* in zephyr/dts/arm/st/f4/stm32f4.dtsi:526 */
				status = "disabled";         /* in zephyr/dts/arm/st/f4/stm32f4.dtsi:527 */
				#pwm-cells = < 0x3 >;        /* in zephyr/dts/arm/st/f4/stm32f4.dtsi:528 */
			};

			/* node '/soc/timers@40014800/counter' defined in zephyr/dts/arm/st/f4/stm32f4.dtsi:531 */
			counter {
				compatible = "st,stm32-counter"; /* in zephyr/dts/arm/st/f4/stm32f4.dtsi:532 */
				status = "disabled";             /* in zephyr/dts/arm/st/f4/stm32f4.dtsi:533 */
			};
		};

		/* node '/soc/rtc@40002800' defined in zephyr/dts/arm/st/f4/stm32f4.dtsi:537 */
		rtc: rtc@40002800 {
			compatible = "st,stm32-rtc";       /* in zephyr/dts/arm/st/f4/stm32f4.dtsi:538 */
			reg = < 0x40002800 0x400 >;        /* in zephyr/dts/arm/st/f4/stm32f4.dtsi:539 */
			interrupts = < 0x29 0x0 >;         /* in zephyr/dts/arm/st/f4/stm32f4.dtsi:540 */
			prescaler = < 0x8000 >;            /* in zephyr/dts/arm/st/f4/stm32f4.dtsi:542 */
			alarms-count = < 0x2 >;            /* in zephyr/dts/arm/st/f4/stm32f4.dtsi:543 */
			alrm-exti-line = < 0x11 >;         /* in zephyr/dts/arm/st/f4/stm32f4.dtsi:544 */
			clocks = < &rcc 0x40 0x10000000 >,
			         < &rcc 0x3 0x2280070 >;   /* in zephyr/boards/iar/stm32f429ii_aca/stm32f429ii_aca.dts:181 */
			status = "okay";                   /* in zephyr/boards/iar/stm32f429ii_aca/stm32f429ii_aca.dts:183 */

			/* node '/soc/rtc@40002800/backup_regs' defined in zephyr/dts/arm/st/f4/stm32f4.dtsi:547 */
			bbram: backup_regs {
				compatible = "st,stm32-bbram"; /* in zephyr/dts/arm/st/f4/stm32f4.dtsi:548 */
				st,backup-regs = < 0x14 >;     /* in zephyr/dts/arm/st/f4/stm32f4.dtsi:549 */
				status = "disabled";           /* in zephyr/dts/arm/st/f4/stm32f4.dtsi:550 */
			};
		};

		/* node '/soc/adc@40012000' defined in zephyr/dts/arm/st/f4/stm32f4.dtsi:554 */
		adc1: adc@40012000 {
			compatible = "st,stm32f4-adc",
			             "st,stm32-adc";                                 /* in zephyr/dts/arm/st/f4/stm32f4.dtsi:555 */
			reg = < 0x40012000 0x400 >;                                  /* in zephyr/dts/arm/st/f4/stm32f4.dtsi:556 */
			clocks = < &rcc 0x44 0x100 >;                                /* in zephyr/dts/arm/st/f4/stm32f4.dtsi:557 */
			clock-names = "adcx";                                        /* in zephyr/dts/arm/st/f4/stm32f4.dtsi:558 */
			interrupts = < 0x12 0x0 >;                                   /* in zephyr/dts/arm/st/f4/stm32f4.dtsi:559 */
			#io-channel-cells = < 0x1 >;                                 /* in zephyr/dts/arm/st/f4/stm32f4.dtsi:560 */
			resolutions = < 0x607804 0x517804 0x427804 0x337804 >;       /* in zephyr/dts/arm/st/f4/stm32f4.dtsi:561 */
			sampling-times = < 0x3 0xf 0x1c 0x38 0x54 0x70 0x90 0x1e0 >; /* in zephyr/dts/arm/st/f4/stm32f4.dtsi:565 */
			st,adc-clock-source = "SYNC";                                /* in zephyr/dts/arm/st/f4/stm32f4.dtsi:566 */
			st,adc-sequencer = "programmable";                           /* in zephyr/dts/arm/st/f4/stm32f4.dtsi:567 */
			st,adc-oversampler = "none";                                 /* in zephyr/dts/arm/st/f4/stm32f4.dtsi:568 */
			st,adc-internal-regulator = "none";                          /* in zephyr/dts/arm/st/f4/stm32f4.dtsi:569 */
			status = "disabled";                                         /* in zephyr/dts/arm/st/f4/stm32f4.dtsi:570 */
			phandle = < 0x42 >;                                          /* in zephyr/dts/arm/st/f4/stm32f427.dtsi:140 */
		};

		/* node '/soc/dma@40026000' defined in zephyr/dts/arm/st/f4/stm32f4.dtsi:573 */
		dma1: dma@40026000 {
			compatible = "st,stm32-dma-v1";                                                      /* in zephyr/dts/arm/st/f4/stm32f4.dtsi:574 */
			#dma-cells = < 0x4 >;                                                                /* in zephyr/dts/arm/st/f4/stm32f4.dtsi:575 */
			reg = < 0x40026000 0x400 >;                                                          /* in zephyr/dts/arm/st/f4/stm32f4.dtsi:576 */
			interrupts = < 0xb 0x0 0xc 0x0 0xd 0x0 0xe 0x0 0xf 0x0 0x10 0x0 0x11 0x0 0x2f 0x0 >; /* in zephyr/dts/arm/st/f4/stm32f4.dtsi:577 */
			clocks = < &rcc 0x30 0x200000 >;                                                     /* in zephyr/dts/arm/st/f4/stm32f4.dtsi:578 */
			status = "disabled";                                                                 /* in zephyr/dts/arm/st/f4/stm32f4.dtsi:579 */
			phandle = < 0xa >;                                                                   /* in zephyr/dts/arm/st/f4/stm32f401.dtsi:58 */
		};

		/* node '/soc/dma@40026400' defined in zephyr/dts/arm/st/f4/stm32f4.dtsi:582 */
		dma2: dma@40026400 {
			compatible = "st,stm32-dma-v1";                                                           /* in zephyr/dts/arm/st/f4/stm32f4.dtsi:583 */
			#dma-cells = < 0x4 >;                                                                     /* in zephyr/dts/arm/st/f4/stm32f4.dtsi:584 */
			reg = < 0x40026400 0x400 >;                                                               /* in zephyr/dts/arm/st/f4/stm32f4.dtsi:585 */
			interrupts = < 0x38 0x0 0x39 0x0 0x3a 0x0 0x3b 0x0 0x3c 0x0 0x44 0x0 0x45 0x0 0x46 0x0 >; /* in zephyr/dts/arm/st/f4/stm32f4.dtsi:586 */
			clocks = < &rcc 0x30 0x400000 >;                                                          /* in zephyr/dts/arm/st/f4/stm32f4.dtsi:587 */
			st,mem2mem;                                                                               /* in zephyr/dts/arm/st/f4/stm32f4.dtsi:588 */
			status = "disabled";                                                                      /* in zephyr/dts/arm/st/f4/stm32f4.dtsi:589 */
			phandle = < 0x3e >;                                                                       /* in zephyr/dts/arm/st/f4/stm32f427.dtsi:122 */
		};

		/* node '/soc/sdmmc@40012c00' defined in zephyr/dts/arm/st/f4/stm32f4.dtsi:592 */
		sdmmc1: sdmmc@40012c00 {
			compatible = "st,stm32-sdmmc"; /* in zephyr/dts/arm/st/f4/stm32f4.dtsi:593 */
			reg = < 0x40012c00 0x400 >;    /* in zephyr/dts/arm/st/f4/stm32f4.dtsi:594 */
			clocks = < &rcc 0x44 0x800 >,
			         < &rcc 0x7 0xff >;    /* in zephyr/dts/arm/st/f4/stm32f4.dtsi:595 */
			resets = < &rctl 0x48b >;      /* in zephyr/dts/arm/st/f4/stm32f4.dtsi:597 */
			interrupts = < 0x31 0x0 >;     /* in zephyr/dts/arm/st/f4/stm32f4.dtsi:598 */
			status = "disabled";           /* in zephyr/dts/arm/st/f4/stm32f4.dtsi:599 */
		};

		/* node '/soc/spi@40003800' defined in zephyr/dts/arm/st/f4/stm32f401.dtsi:21 */
		spi2: spi@40003800 {
			compatible = "st,stm32-spi";   /* in zephyr/dts/arm/st/f4/stm32f401.dtsi:22 */
			#address-cells = < 0x1 >;      /* in zephyr/dts/arm/st/f4/stm32f401.dtsi:23 */
			#size-cells = < 0x0 >;         /* in zephyr/dts/arm/st/f4/stm32f401.dtsi:24 */
			reg = < 0x40003800 0x400 >;    /* in zephyr/dts/arm/st/f4/stm32f401.dtsi:25 */
			clocks = < &rcc 0x40 0x4000 >; /* in zephyr/dts/arm/st/f4/stm32f401.dtsi:26 */
			interrupts = < 0x24 0x5 >;     /* in zephyr/dts/arm/st/f4/stm32f401.dtsi:27 */
			status = "disabled";           /* in zephyr/dts/arm/st/f4/stm32f401.dtsi:28 */
		};

		/* node '/soc/spi@40003c00' defined in zephyr/dts/arm/st/f4/stm32f401.dtsi:31 */
		spi3: spi@40003c00 {
			compatible = "st,stm32-spi";   /* in zephyr/dts/arm/st/f4/stm32f401.dtsi:32 */
			#address-cells = < 0x1 >;      /* in zephyr/dts/arm/st/f4/stm32f401.dtsi:33 */
			#size-cells = < 0x0 >;         /* in zephyr/dts/arm/st/f4/stm32f401.dtsi:34 */
			reg = < 0x40003c00 0x400 >;    /* in zephyr/dts/arm/st/f4/stm32f401.dtsi:35 */
			clocks = < &rcc 0x40 0x8000 >; /* in zephyr/dts/arm/st/f4/stm32f401.dtsi:36 */
			interrupts = < 0x33 0x5 >;     /* in zephyr/dts/arm/st/f4/stm32f401.dtsi:37 */
			status = "disabled";           /* in zephyr/dts/arm/st/f4/stm32f401.dtsi:38 */
		};

		/* node '/soc/spi@40013400' defined in zephyr/dts/arm/st/f4/stm32f401.dtsi:41 */
		spi4: spi@40013400 {
			compatible = "st,stm32-spi";   /* in zephyr/dts/arm/st/f4/stm32f427.dtsi:67 */
			#address-cells = < 0x1 >;      /* in zephyr/dts/arm/st/f4/stm32f427.dtsi:68 */
			#size-cells = < 0x0 >;         /* in zephyr/dts/arm/st/f4/stm32f427.dtsi:69 */
			reg = < 0x40013400 0x400 >;    /* in zephyr/dts/arm/st/f4/stm32f427.dtsi:70 */
			clocks = < &rcc 0x44 0x2000 >; /* in zephyr/dts/arm/st/f4/stm32f427.dtsi:71 */
			interrupts = < 0x54 0x5 >;     /* in zephyr/dts/arm/st/f4/stm32f427.dtsi:72 */
			status = "disabled";           /* in zephyr/dts/arm/st/f4/stm32f427.dtsi:73 */
		};

		/* node '/soc/i2s@40003800' defined in zephyr/dts/arm/st/f4/stm32f401.dtsi:51 */
		i2s2: i2s@40003800 {
			compatible = "st,stm32-i2s";        /* in zephyr/dts/arm/st/f4/stm32f401.dtsi:52 */
			#address-cells = < 0x1 >;           /* in zephyr/dts/arm/st/f4/stm32f401.dtsi:53 */
			#size-cells = < 0x0 >;              /* in zephyr/dts/arm/st/f4/stm32f401.dtsi:54 */
			reg = < 0x40003800 0x400 >;         /* in zephyr/dts/arm/st/f4/stm32f401.dtsi:55 */
			clocks = < &rcc 0x40 0x4000 >;      /* in zephyr/dts/arm/st/f4/stm32f401.dtsi:56 */
			interrupts = < 0x24 0x5 >;          /* in zephyr/dts/arm/st/f4/stm32f401.dtsi:57 */
			dmas = < &dma1 0x4 0x0 0x400 0x3 >,
			       < &dma1 0x3 0x0 0x400 0x3 >; /* in zephyr/dts/arm/st/f4/stm32f401.dtsi:58 */
			dma-names = "tx",
			            "rx";                   /* in zephyr/dts/arm/st/f4/stm32f401.dtsi:60 */
			status = "disabled";                /* in zephyr/dts/arm/st/f4/stm32f401.dtsi:61 */
		};

		/* node '/soc/i2s@40003c00' defined in zephyr/dts/arm/st/f4/stm32f401.dtsi:64 */
		i2s3: i2s@40003c00 {
			compatible = "st,stm32-i2s";        /* in zephyr/dts/arm/st/f4/stm32f401.dtsi:65 */
			#address-cells = < 0x1 >;           /* in zephyr/dts/arm/st/f4/stm32f401.dtsi:66 */
			#size-cells = < 0x0 >;              /* in zephyr/dts/arm/st/f4/stm32f401.dtsi:67 */
			reg = < 0x40003c00 0x400 >;         /* in zephyr/dts/arm/st/f4/stm32f401.dtsi:68 */
			clocks = < &rcc 0x40 0x8000 >;      /* in zephyr/dts/arm/st/f4/stm32f401.dtsi:69 */
			interrupts = < 0x33 0x5 >;          /* in zephyr/dts/arm/st/f4/stm32f401.dtsi:70 */
			dmas = < &dma1 0x5 0x0 0x400 0x3 >,
			       < &dma1 0x0 0x0 0x400 0x3 >; /* in zephyr/dts/arm/st/f4/stm32f401.dtsi:71 */
			dma-names = "tx",
			            "rx";                   /* in zephyr/dts/arm/st/f4/stm32f401.dtsi:73 */
			status = "disabled";                /* in zephyr/dts/arm/st/f4/stm32f401.dtsi:74 */
		};

		/* node '/soc/serial@40004800' defined in zephyr/dts/arm/st/f4/stm32f405.dtsi:51 */
		usart3: serial@40004800 {
			compatible = "st,stm32-usart",
			             "st,stm32-uart";   /* in zephyr/dts/arm/st/f4/stm32f405.dtsi:52 */
			reg = < 0x40004800 0x400 >;     /* in zephyr/dts/arm/st/f4/stm32f405.dtsi:53 */
			clocks = < &rcc 0x40 0x40000 >; /* in zephyr/dts/arm/st/f4/stm32f405.dtsi:54 */
			resets = < &rctl 0x412 >;       /* in zephyr/dts/arm/st/f4/stm32f405.dtsi:55 */
			interrupts = < 0x27 0x0 >;      /* in zephyr/dts/arm/st/f4/stm32f405.dtsi:56 */
			status = "disabled";            /* in zephyr/dts/arm/st/f4/stm32f405.dtsi:57 */
		};

		/* node '/soc/serial@40004c00' defined in zephyr/dts/arm/st/f4/stm32f405.dtsi:60 */
		uart4: serial@40004c00 {
			compatible = "st,stm32-uart";   /* in zephyr/dts/arm/st/f4/stm32f405.dtsi:61 */
			reg = < 0x40004c00 0x400 >;     /* in zephyr/dts/arm/st/f4/stm32f405.dtsi:62 */
			clocks = < &rcc 0x40 0x80000 >; /* in zephyr/dts/arm/st/f4/stm32f405.dtsi:63 */
			resets = < &rctl 0x413 >;       /* in zephyr/dts/arm/st/f4/stm32f405.dtsi:64 */
			interrupts = < 0x34 0x0 >;      /* in zephyr/dts/arm/st/f4/stm32f405.dtsi:65 */
			status = "disabled";            /* in zephyr/dts/arm/st/f4/stm32f405.dtsi:66 */
		};

		/* node '/soc/serial@40005000' defined in zephyr/dts/arm/st/f4/stm32f405.dtsi:69 */
		uart5: serial@40005000 {
			compatible = "st,stm32-uart";    /* in zephyr/dts/arm/st/f4/stm32f405.dtsi:70 */
			reg = < 0x40005000 0x400 >;      /* in zephyr/dts/arm/st/f4/stm32f405.dtsi:71 */
			clocks = < &rcc 0x40 0x100000 >; /* in zephyr/dts/arm/st/f4/stm32f405.dtsi:72 */
			resets = < &rctl 0x414 >;        /* in zephyr/dts/arm/st/f4/stm32f405.dtsi:73 */
			interrupts = < 0x35 0x0 >;       /* in zephyr/dts/arm/st/f4/stm32f405.dtsi:74 */
			status = "disabled";             /* in zephyr/dts/arm/st/f4/stm32f405.dtsi:75 */
		};

		/* node '/soc/timers@40001000' defined in zephyr/dts/arm/st/f4/stm32f405.dtsi:78 */
		timers6: timers@40001000 {
			compatible = "st,stm32-timers"; /* in zephyr/dts/arm/st/f4/stm32f405.dtsi:79 */
			reg = < 0x40001000 0x400 >;     /* in zephyr/dts/arm/st/f4/stm32f405.dtsi:80 */
			clocks = < &rcc 0x40 0x10 >,
			         < &rcc 0xc 0xff >;     /* in zephyr/dts/arm/st/f4/stm32f405.dtsi:81 */
			resets = < &rctl 0x404 >;       /* in zephyr/dts/arm/st/f4/stm32f405.dtsi:83 */
			interrupts = < 0x36 0x0 >;      /* in zephyr/dts/arm/st/f4/stm32f405.dtsi:84 */
			interrupt-names = "global";     /* in zephyr/dts/arm/st/f4/stm32f405.dtsi:85 */
			st,prescaler = < 0x0 >;         /* in zephyr/dts/arm/st/f4/stm32f405.dtsi:86 */
			status = "disabled";            /* in zephyr/dts/arm/st/f4/stm32f405.dtsi:87 */

			/* node '/soc/timers@40001000/counter' defined in zephyr/dts/arm/st/f4/stm32f405.dtsi:89 */
			counter {
				compatible = "st,stm32-counter"; /* in zephyr/dts/arm/st/f4/stm32f405.dtsi:90 */
				status = "disabled";             /* in zephyr/dts/arm/st/f4/stm32f405.dtsi:91 */
			};
		};

		/* node '/soc/timers@40001400' defined in zephyr/dts/arm/st/f4/stm32f405.dtsi:95 */
		timers7: timers@40001400 {
			compatible = "st,stm32-timers"; /* in zephyr/dts/arm/st/f4/stm32f405.dtsi:96 */
			reg = < 0x40001400 0x400 >;     /* in zephyr/dts/arm/st/f4/stm32f405.dtsi:97 */
			clocks = < &rcc 0x40 0x20 >,
			         < &rcc 0xc 0xff >;     /* in zephyr/dts/arm/st/f4/stm32f405.dtsi:98 */
			resets = < &rctl 0x405 >;       /* in zephyr/dts/arm/st/f4/stm32f405.dtsi:100 */
			interrupts = < 0x37 0x0 >;      /* in zephyr/dts/arm/st/f4/stm32f405.dtsi:101 */
			interrupt-names = "global";     /* in zephyr/dts/arm/st/f4/stm32f405.dtsi:102 */
			st,prescaler = < 0x0 >;         /* in zephyr/dts/arm/st/f4/stm32f405.dtsi:103 */
			status = "disabled";            /* in zephyr/dts/arm/st/f4/stm32f405.dtsi:104 */

			/* node '/soc/timers@40001400/counter' defined in zephyr/dts/arm/st/f4/stm32f405.dtsi:106 */
			counter {
				compatible = "st,stm32-counter"; /* in zephyr/dts/arm/st/f4/stm32f405.dtsi:107 */
				status = "disabled";             /* in zephyr/dts/arm/st/f4/stm32f405.dtsi:108 */
			};
		};

		/* node '/soc/timers@40010400' defined in zephyr/dts/arm/st/f4/stm32f405.dtsi:112 */
		timers8: timers@40010400 {
			compatible = "st,stm32-timers"; /* in zephyr/dts/arm/st/f4/stm32f405.dtsi:113 */
			reg = < 0x40010400 0x400 >;     /* in zephyr/dts/arm/st/f4/stm32f405.dtsi:114 */
			clocks = < &rcc 0x44 0x2 >,
			         < &rcc 0xd 0xff >;     /* in zephyr/dts/arm/st/f4/stm32f405.dtsi:115 */
			resets = < &rctl 0x481 >;       /* in zephyr/dts/arm/st/f4/stm32f405.dtsi:117 */
			interrupts = < 0x2b 0x0 >,
			             < 0x2c 0x0 >,
			             < 0x2d 0x0 >,
			             < 0x2e 0x0 >;      /* in zephyr/dts/arm/st/f4/stm32f405.dtsi:118 */
			interrupt-names = "brk",
			                  "up",
			                  "trgcom",
			                  "cc";         /* in zephyr/dts/arm/st/f4/stm32f405.dtsi:119 */
			st,prescaler = < 0x0 >;         /* in zephyr/dts/arm/st/f4/stm32f405.dtsi:120 */
			status = "disabled";            /* in zephyr/dts/arm/st/f4/stm32f405.dtsi:121 */

			/* node '/soc/timers@40010400/pwm' defined in zephyr/dts/arm/st/f4/stm32f405.dtsi:123 */
			pwm {
				compatible = "st,stm32-pwm"; /* in zephyr/dts/arm/st/f4/stm32f405.dtsi:124 */
				status = "disabled";         /* in zephyr/dts/arm/st/f4/stm32f405.dtsi:125 */
				#pwm-cells = < 0x3 >;        /* in zephyr/dts/arm/st/f4/stm32f405.dtsi:126 */
			};

			/* node '/soc/timers@40010400/qdec' defined in zephyr/dts/arm/st/f4/stm32f405.dtsi:129 */
			qdec {
				compatible = "st,stm32-qdec";    /* in zephyr/dts/arm/st/f4/stm32f405.dtsi:130 */
				st,input-filter-level = < 0x0 >; /* in zephyr/dts/arm/st/f4/stm32f405.dtsi:131 */
				status = "disabled";             /* in zephyr/dts/arm/st/f4/stm32f405.dtsi:132 */
			};
		};

		/* node '/soc/timers@40001800' defined in zephyr/dts/arm/st/f4/stm32f405.dtsi:136 */
		timers12: timers@40001800 {
			compatible = "st,stm32-timers"; /* in zephyr/dts/arm/st/f4/stm32f405.dtsi:137 */
			reg = < 0x40001800 0x400 >;     /* in zephyr/dts/arm/st/f4/stm32f405.dtsi:138 */
			clocks = < &rcc 0x40 0x40 >,
			         < &rcc 0xc 0xff >;     /* in zephyr/dts/arm/st/f4/stm32f405.dtsi:139 */
			resets = < &rctl 0x406 >;       /* in zephyr/dts/arm/st/f4/stm32f405.dtsi:141 */
			interrupts = < 0x2b 0x0 >;      /* in zephyr/dts/arm/st/f4/stm32f405.dtsi:142 */
			interrupt-names = "global";     /* in zephyr/dts/arm/st/f4/stm32f405.dtsi:143 */
			st,prescaler = < 0x0 >;         /* in zephyr/dts/arm/st/f4/stm32f405.dtsi:144 */
			status = "disabled";            /* in zephyr/dts/arm/st/f4/stm32f405.dtsi:145 */

			/* node '/soc/timers@40001800/pwm' defined in zephyr/dts/arm/st/f4/stm32f405.dtsi:147 */
			pwm {
				compatible = "st,stm32-pwm"; /* in zephyr/dts/arm/st/f4/stm32f405.dtsi:148 */
				status = "disabled";         /* in zephyr/dts/arm/st/f4/stm32f405.dtsi:149 */
				#pwm-cells = < 0x3 >;        /* in zephyr/dts/arm/st/f4/stm32f405.dtsi:150 */
			};

			/* node '/soc/timers@40001800/counter' defined in zephyr/dts/arm/st/f4/stm32f405.dtsi:153 */
			counter {
				compatible = "st,stm32-counter"; /* in zephyr/dts/arm/st/f4/stm32f405.dtsi:154 */
				status = "disabled";             /* in zephyr/dts/arm/st/f4/stm32f405.dtsi:155 */
			};
		};

		/* node '/soc/timers@40001c00' defined in zephyr/dts/arm/st/f4/stm32f405.dtsi:159 */
		timers13: timers@40001c00 {
			compatible = "st,stm32-timers"; /* in zephyr/dts/arm/st/f4/stm32f405.dtsi:160 */
			reg = < 0x40001c00 0x400 >;     /* in zephyr/dts/arm/st/f4/stm32f405.dtsi:161 */
			clocks = < &rcc 0x40 0x80 >,
			         < &rcc 0xc 0xff >;     /* in zephyr/dts/arm/st/f4/stm32f405.dtsi:162 */
			resets = < &rctl 0x407 >;       /* in zephyr/dts/arm/st/f4/stm32f405.dtsi:164 */
			interrupts = < 0x2c 0x0 >;      /* in zephyr/dts/arm/st/f4/stm32f405.dtsi:165 */
			interrupt-names = "global";     /* in zephyr/dts/arm/st/f4/stm32f405.dtsi:166 */
			st,prescaler = < 0x0 >;         /* in zephyr/dts/arm/st/f4/stm32f405.dtsi:167 */
			status = "disabled";            /* in zephyr/dts/arm/st/f4/stm32f405.dtsi:168 */

			/* node '/soc/timers@40001c00/pwm' defined in zephyr/dts/arm/st/f4/stm32f405.dtsi:170 */
			pwm {
				compatible = "st,stm32-pwm"; /* in zephyr/dts/arm/st/f4/stm32f405.dtsi:171 */
				status = "disabled";         /* in zephyr/dts/arm/st/f4/stm32f405.dtsi:172 */
				#pwm-cells = < 0x3 >;        /* in zephyr/dts/arm/st/f4/stm32f405.dtsi:173 */
			};

			/* node '/soc/timers@40001c00/counter' defined in zephyr/dts/arm/st/f4/stm32f405.dtsi:176 */
			counter {
				compatible = "st,stm32-counter"; /* in zephyr/dts/arm/st/f4/stm32f405.dtsi:177 */
				status = "disabled";             /* in zephyr/dts/arm/st/f4/stm32f405.dtsi:178 */
			};
		};

		/* node '/soc/timers@40002000' defined in zephyr/dts/arm/st/f4/stm32f405.dtsi:182 */
		timers14: timers@40002000 {
			compatible = "st,stm32-timers"; /* in zephyr/dts/arm/st/f4/stm32f405.dtsi:183 */
			reg = < 0x40002000 0x400 >;     /* in zephyr/dts/arm/st/f4/stm32f405.dtsi:184 */
			clocks = < &rcc 0x40 0x100 >,
			         < &rcc 0xc 0xff >;     /* in zephyr/dts/arm/st/f4/stm32f405.dtsi:185 */
			resets = < &rctl 0x408 >;       /* in zephyr/dts/arm/st/f4/stm32f405.dtsi:187 */
			interrupts = < 0x2d 0x0 >;      /* in zephyr/dts/arm/st/f4/stm32f405.dtsi:188 */
			interrupt-names = "global";     /* in zephyr/dts/arm/st/f4/stm32f405.dtsi:189 */
			st,prescaler = < 0x0 >;         /* in zephyr/dts/arm/st/f4/stm32f405.dtsi:190 */
			status = "disabled";            /* in zephyr/dts/arm/st/f4/stm32f405.dtsi:191 */

			/* node '/soc/timers@40002000/pwm' defined in zephyr/dts/arm/st/f4/stm32f405.dtsi:193 */
			pwm {
				compatible = "st,stm32-pwm"; /* in zephyr/dts/arm/st/f4/stm32f405.dtsi:194 */
				status = "disabled";         /* in zephyr/dts/arm/st/f4/stm32f405.dtsi:195 */
				#pwm-cells = < 0x3 >;        /* in zephyr/dts/arm/st/f4/stm32f405.dtsi:196 */
			};

			/* node '/soc/timers@40002000/counter' defined in zephyr/dts/arm/st/f4/stm32f405.dtsi:199 */
			counter {
				compatible = "st,stm32-counter"; /* in zephyr/dts/arm/st/f4/stm32f405.dtsi:200 */
				status = "disabled";             /* in zephyr/dts/arm/st/f4/stm32f405.dtsi:201 */
			};
		};

		/* node '/soc/usb@40040000' defined in zephyr/dts/arm/st/f4/stm32f405.dtsi:205 */
		usbotg_hs: zephyr_udc0: usb@40040000 {
			compatible = "st,stm32-otghs";                                               /* in zephyr/dts/arm/st/f4/stm32f405.dtsi:206 */
			reg = < 0x40040000 0x40000 >;                                                /* in zephyr/dts/arm/st/f4/stm32f405.dtsi:207 */
			interrupts = < 0x4d 0x0 >,
			             < 0x4a 0x0 >,
			             < 0x4b 0x0 >;                                                   /* in zephyr/dts/arm/st/f4/stm32f405.dtsi:208 */
			interrupt-names = "otghs",
			                  "ep1_out",
			                  "ep1_in";                                                  /* in zephyr/dts/arm/st/f4/stm32f405.dtsi:209 */
			num-bidir-endpoints = < 0x6 >;                                               /* in zephyr/dts/arm/st/f4/stm32f405.dtsi:210 */
			ram-size = < 0x1000 >;                                                       /* in zephyr/dts/arm/st/f4/stm32f405.dtsi:211 */
			maximum-speed = "full-speed";                                                /* in zephyr/dts/arm/st/f4/stm32f405.dtsi:212 */
			phys = < &otghs_fs_phy >;                                                    /* in zephyr/dts/arm/st/f4/stm32f405.dtsi:213 */
			clocks = < &rcc 0x30 0x20000000 >,
			         < &rcc 0x7 0xff >;                                                  /* in zephyr/dts/arm/st/f4/stm32f405.dtsi:214 */
			pinctrl-0 = < &usb_otg_hs_dm_pb14 &usb_otg_hs_dp_pb15 &usb_otg_hs_id_pb12 >; /* in zephyr/boards/iar/stm32f429ii_aca/stm32f429ii_aca.dts:273 */
			pinctrl-names = "default";                                                   /* in zephyr/boards/iar/stm32f429ii_aca/stm32f429ii_aca.dts:274 */
			status = "okay";                                                             /* in zephyr/boards/iar/stm32f429ii_aca/stm32f429ii_aca.dts:275 */
		};

		/* node '/soc/can@40006400' defined in zephyr/dts/arm/st/f4/stm32f405.dtsi:219 */
		can1: can@40006400 {
			compatible = "st,stm32-bxcan";    /* in zephyr/dts/arm/st/f4/stm32f405.dtsi:220 */
			reg = < 0x40006400 0x400 >;       /* in zephyr/dts/arm/st/f4/stm32f405.dtsi:221 */
			interrupts = < 0x13 0x0 >,
			             < 0x14 0x0 >,
			             < 0x15 0x0 >,
			             < 0x16 0x0 >;        /* in zephyr/dts/arm/st/f4/stm32f405.dtsi:222 */
			interrupt-names = "TX",
			                  "RX0",
			                  "RX1",
			                  "SCE";          /* in zephyr/dts/arm/st/f4/stm32f405.dtsi:223 */
			clocks = < &rcc 0x40 0x2000000 >; /* in zephyr/dts/arm/st/f4/stm32f405.dtsi:224 */
			status = "disabled";              /* in zephyr/dts/arm/st/f4/stm32f405.dtsi:225 */
		};

		/* node '/soc/can@40006800' defined in zephyr/dts/arm/st/f4/stm32f405.dtsi:228 */
		can2: can@40006800 {
			compatible = "st,stm32-bxcan";    /* in zephyr/dts/arm/st/f4/stm32f405.dtsi:229 */
			reg = < 0x40006800 0x400 >;       /* in zephyr/dts/arm/st/f4/stm32f405.dtsi:230 */
			interrupts = < 0x3f 0x0 >,
			             < 0x40 0x0 >,
			             < 0x41 0x0 >,
			             < 0x42 0x0 >;        /* in zephyr/dts/arm/st/f4/stm32f405.dtsi:231 */
			interrupt-names = "TX",
			                  "RX0",
			                  "RX1",
			                  "SCE";          /* in zephyr/dts/arm/st/f4/stm32f405.dtsi:232 */
			clocks = < &rcc 0x40 0x6000000 >; /* in zephyr/dts/arm/st/f4/stm32f405.dtsi:234 */
			master-can-reg = < 0x40006400 >;  /* in zephyr/dts/arm/st/f4/stm32f405.dtsi:235 */
			status = "disabled";              /* in zephyr/dts/arm/st/f4/stm32f405.dtsi:236 */
		};

		/* node '/soc/rng@50060800' defined in zephyr/dts/arm/st/f4/stm32f405.dtsi:239 */
		rng: rng@50060800 {
			compatible = "st,stm32-rng"; /* in zephyr/dts/arm/st/f4/stm32f405.dtsi:240 */
			reg = < 0x50060800 0x400 >;  /* in zephyr/dts/arm/st/f4/stm32f405.dtsi:241 */
			interrupts = < 0x50 0x0 >;   /* in zephyr/dts/arm/st/f4/stm32f405.dtsi:242 */
			clocks = < &rcc 0x34 0x40 >; /* in zephyr/dts/arm/st/f4/stm32f405.dtsi:243 */
			status = "disabled";         /* in zephyr/dts/arm/st/f4/stm32f405.dtsi:244 */
		};

		/* node '/soc/memory@40024000' defined in zephyr/dts/arm/st/f4/stm32f405.dtsi:247 */
		backup_sram: memory@40024000 {
			compatible = "zephyr,memory-region",
			             "st,stm32-backup-sram";  /* in zephyr/dts/arm/st/f4/stm32f405.dtsi:248 */
			reg = < 0x40024000 0x1000 >;          /* in zephyr/dts/arm/st/f4/stm32f405.dtsi:249 */
			clocks = < &rcc 0x30 0x40000 >;       /* in zephyr/dts/arm/st/f4/stm32f405.dtsi:250 */
			zephyr,memory-region = "BACKUP_SRAM"; /* in zephyr/dts/arm/st/f4/stm32f405.dtsi:251 */
			status = "disabled";                  /* in zephyr/dts/arm/st/f4/stm32f405.dtsi:252 */
		};

		/* node '/soc/adc@40012100' defined in zephyr/dts/arm/st/f4/stm32f405.dtsi:255 */
		adc2: adc@40012100 {
			reg = < 0x40012100 0x50 >;                                   /* in zephyr/dts/arm/st/f4/stm32f405.dtsi:257 */
			clocks = < &rcc 0x44 0x200 >;                                /* in zephyr/dts/arm/st/f4/stm32f405.dtsi:258 */
			clock-names = "adcx";                                        /* in zephyr/dts/arm/st/f4/stm32f405.dtsi:259 */
			interrupts = < 0x12 0x0 >;                                   /* in zephyr/dts/arm/st/f4/stm32f405.dtsi:260 */
			#io-channel-cells = < 0x1 >;                                 /* in zephyr/dts/arm/st/f4/stm32f405.dtsi:261 */
			resolutions = < 0x607804 0x517804 0x427804 0x337804 >;       /* in zephyr/dts/arm/st/f4/stm32f405.dtsi:262 */
			sampling-times = < 0x3 0xf 0x1c 0x38 0x54 0x70 0x90 0x1e0 >; /* in zephyr/dts/arm/st/f4/stm32f405.dtsi:266 */
			st,adc-clock-source = "SYNC";                                /* in zephyr/dts/arm/st/f4/stm32f405.dtsi:267 */
			st,adc-sequencer = "programmable";                           /* in zephyr/dts/arm/st/f4/stm32f405.dtsi:268 */
			st,adc-oversampler = "none";                                 /* in zephyr/dts/arm/st/f4/stm32f405.dtsi:269 */
			st,adc-internal-regulator = "none";                          /* in zephyr/dts/arm/st/f4/stm32f405.dtsi:270 */
			compatible = "st,stm32f4-adc",
			             "st,stm32-adc";                                 /* in zephyr/boards/iar/stm32f429ii_aca/stm32f429ii_aca.dts:248 */
			pinctrl-0 = < &adc2_in6_pa6 >;                               /* in zephyr/boards/iar/stm32f429ii_aca/stm32f429ii_aca.dts:249 */
			pinctrl-names = "default";                                   /* in zephyr/boards/iar/stm32f429ii_aca/stm32f429ii_aca.dts:250 */
			st,adc-prescaler = < 0x2 >;                                  /* in zephyr/boards/iar/stm32f429ii_aca/stm32f429ii_aca.dts:251 */
			status = "okay";                                             /* in zephyr/boards/iar/stm32f429ii_aca/stm32f429ii_aca.dts:252 */
			#address-cells = < 0x1 >;                                    /* in zephyr/boards/iar/stm32f429ii_aca/stm32f429ii_aca.dts:254 */
			#size-cells = < 0x0 >;                                       /* in zephyr/boards/iar/stm32f429ii_aca/stm32f429ii_aca.dts:255 */

			/* node '/soc/adc@40012100/channel@6' defined in zephyr/boards/iar/stm32f429ii_aca/stm32f429ii_aca.dts:257 */
			channel@6 {
				reg = < 0x6 >;                         /* in zephyr/boards/iar/stm32f429ii_aca/stm32f429ii_aca.dts:258 */
				zephyr,gain = "ADC_GAIN_1";            /* in zephyr/boards/iar/stm32f429ii_aca/stm32f429ii_aca.dts:259 */
				zephyr,reference = "ADC_REF_INTERNAL"; /* in zephyr/boards/iar/stm32f429ii_aca/stm32f429ii_aca.dts:260 */
				zephyr,acquisition-time = < 0x0 >;     /* in zephyr/boards/iar/stm32f429ii_aca/stm32f429ii_aca.dts:261 */
				zephyr,resolution = < 0xc >;           /* in zephyr/boards/iar/stm32f429ii_aca/stm32f429ii_aca.dts:262 */
			};
		};

		/* node '/soc/adc@40012200' defined in zephyr/dts/arm/st/f4/stm32f405.dtsi:274 */
		adc3: adc@40012200 {
			compatible = "st,stm32-adc";                                 /* in zephyr/dts/arm/st/f4/stm32f405.dtsi:275 */
			reg = < 0x40012200 0x50 >;                                   /* in zephyr/dts/arm/st/f4/stm32f405.dtsi:276 */
			clocks = < &rcc 0x44 0x400 >;                                /* in zephyr/dts/arm/st/f4/stm32f405.dtsi:277 */
			clock-names = "adcx";                                        /* in zephyr/dts/arm/st/f4/stm32f405.dtsi:278 */
			interrupts = < 0x12 0x0 >;                                   /* in zephyr/dts/arm/st/f4/stm32f405.dtsi:279 */
			#io-channel-cells = < 0x1 >;                                 /* in zephyr/dts/arm/st/f4/stm32f405.dtsi:280 */
			resolutions = < 0x607804 0x517804 0x427804 0x337804 >;       /* in zephyr/dts/arm/st/f4/stm32f405.dtsi:281 */
			sampling-times = < 0x3 0xf 0x1c 0x38 0x54 0x70 0x90 0x1e0 >; /* in zephyr/dts/arm/st/f4/stm32f405.dtsi:285 */
			st,adc-clock-source = "SYNC";                                /* in zephyr/dts/arm/st/f4/stm32f405.dtsi:286 */
			st,adc-sequencer = "programmable";                           /* in zephyr/dts/arm/st/f4/stm32f405.dtsi:287 */
			st,adc-oversampler = "none";                                 /* in zephyr/dts/arm/st/f4/stm32f405.dtsi:288 */
			st,adc-internal-regulator = "none";                          /* in zephyr/dts/arm/st/f4/stm32f405.dtsi:289 */
			status = "disabled";                                         /* in zephyr/dts/arm/st/f4/stm32f405.dtsi:290 */
		};

		/* node '/soc/dac@40007400' defined in zephyr/dts/arm/st/f4/stm32f405.dtsi:293 */
		dac1: dac@40007400 {
			compatible = "st,stm32-dac";       /* in zephyr/dts/arm/st/f4/stm32f429.dtsi:15 */
			reg = < 0x40007400 0x400 >;        /* in zephyr/dts/arm/st/f4/stm32f429.dtsi:16 */
			clocks = < &rcc 0x40 0x20000000 >; /* in zephyr/dts/arm/st/f4/stm32f429.dtsi:17 */
			#io-channel-cells = < 0x1 >;       /* in zephyr/dts/arm/st/f4/stm32f429.dtsi:19 */
			pinctrl-0 = < &dac_out2_pa5 >;     /* in zephyr/boards/iar/stm32f429ii_aca/stm32f429ii_aca.dts:267 */
			pinctrl-names = "default";         /* in zephyr/boards/iar/stm32f429ii_aca/stm32f429ii_aca.dts:268 */
			status = "okay";                   /* in zephyr/boards/iar/stm32f429ii_aca/stm32f429ii_aca.dts:269 */
		};

		/* node '/soc/ethernet@40028000' defined in zephyr/dts/arm/st/f4/stm32f407.dtsi:13 */
		ethernet@40028000 {
			reg = < 0x40028000 0x8000 >;                 /* in zephyr/dts/arm/st/f4/stm32f407.dtsi:14 */
			compatible = "st,stm32-ethernet-controller"; /* in zephyr/dts/arm/st/f4/stm32f407.dtsi:15 */
			clock-names = "stm-eth";                     /* in zephyr/dts/arm/st/f4/stm32f407.dtsi:16 */
			clocks = < &rcc 0x30 0x2000000 >;            /* in zephyr/dts/arm/st/f4/stm32f407.dtsi:17 */

			/* node '/soc/ethernet@40028000/ethernet' defined in zephyr/dts/arm/st/f4/stm32f407.dtsi:19 */
			mac: ethernet {
				compatible = "st,stm32-ethernet";  /* in zephyr/dts/arm/st/f4/stm32f407.dtsi:20 */
				interrupts = < 0x3d 0x0 >;         /* in zephyr/dts/arm/st/f4/stm32f407.dtsi:21 */
				clock-names = "mac-clk-tx",
				              "mac-clk-rx",
				              "mac-clk-ptp";       /* in zephyr/dts/arm/st/f4/stm32f407.dtsi:22 */
				clocks = < &rcc 0x30 0x4000000 >,
				         < &rcc 0x30 0x8000000 >,
				         < &rcc 0x30 0x10000000 >; /* in zephyr/dts/arm/st/f4/stm32f407.dtsi:24 */
				status = "disabled";               /* in zephyr/dts/arm/st/f4/stm32f407.dtsi:27 */
			};

			/* node '/soc/ethernet@40028000/mdio' defined in zephyr/dts/arm/st/f4/stm32f407.dtsi:30 */
			mdio: mdio {
				compatible = "st,stm32-mdio"; /* in zephyr/dts/arm/st/f4/stm32f407.dtsi:31 */
				#address-cells = < 0x1 >;     /* in zephyr/dts/arm/st/f4/stm32f407.dtsi:32 */
				#size-cells = < 0x0 >;        /* in zephyr/dts/arm/st/f4/stm32f407.dtsi:33 */
				status = "disabled";          /* in zephyr/dts/arm/st/f4/stm32f407.dtsi:34 */
			};
		};

		/* node '/soc/serial@40007800' defined in zephyr/dts/arm/st/f4/stm32f427.dtsi:48 */
		uart7: serial@40007800 {
			compatible = "st,stm32-uart";      /* in zephyr/dts/arm/st/f4/stm32f427.dtsi:49 */
			reg = < 0x40007800 0x400 >;        /* in zephyr/dts/arm/st/f4/stm32f427.dtsi:50 */
			clocks = < &rcc 0x40 0x40000000 >; /* in zephyr/dts/arm/st/f4/stm32f427.dtsi:51 */
			resets = < &rctl 0x41e >;          /* in zephyr/dts/arm/st/f4/stm32f427.dtsi:52 */
			interrupts = < 0x52 0x0 >;         /* in zephyr/dts/arm/st/f4/stm32f427.dtsi:53 */
			status = "disabled";               /* in zephyr/dts/arm/st/f4/stm32f427.dtsi:54 */
		};

		/* node '/soc/serial@40007c00' defined in zephyr/dts/arm/st/f4/stm32f427.dtsi:57 */
		uart8: serial@40007c00 {
			compatible = "st,stm32-uart";      /* in zephyr/dts/arm/st/f4/stm32f427.dtsi:58 */
			reg = < 0x40007c00 0x400 >;        /* in zephyr/dts/arm/st/f4/stm32f427.dtsi:59 */
			clocks = < &rcc 0x40 0x80000000 >; /* in zephyr/dts/arm/st/f4/stm32f427.dtsi:60 */
			resets = < &rctl 0x41f >;          /* in zephyr/dts/arm/st/f4/stm32f427.dtsi:61 */
			interrupts = < 0x53 0x0 >;         /* in zephyr/dts/arm/st/f4/stm32f427.dtsi:62 */
			status = "disabled";               /* in zephyr/dts/arm/st/f4/stm32f427.dtsi:63 */
		};

		/* node '/soc/spi@40015000' defined in zephyr/dts/arm/st/f4/stm32f427.dtsi:79 */
		spi5: spi@40015000 {
			compatible = "st,stm32-spi";                                               /* in zephyr/dts/arm/st/f4/stm32f427.dtsi:80 */
			#address-cells = < 0x1 >;                                                  /* in zephyr/dts/arm/st/f4/stm32f427.dtsi:81 */
			#size-cells = < 0x0 >;                                                     /* in zephyr/dts/arm/st/f4/stm32f427.dtsi:82 */
			reg = < 0x40015000 0x400 >;                                                /* in zephyr/dts/arm/st/f4/stm32f427.dtsi:83 */
			clocks = < &rcc 0x44 0x100000 >;                                           /* in zephyr/dts/arm/st/f4/stm32f427.dtsi:84 */
			interrupts = < 0x55 0x5 >;                                                 /* in zephyr/dts/arm/st/f4/stm32f427.dtsi:85 */
			pinctrl-0 = < &spi5_nss_pf6 &spi5_sck_pf7 &spi5_miso_pf8 &spi5_mosi_pf9 >; /* in zephyr/boards/iar/stm32f429ii_aca/stm32f429ii_aca.dts:201 */
			pinctrl-names = "default";                                                 /* in zephyr/boards/iar/stm32f429ii_aca/stm32f429ii_aca.dts:203 */
			status = "okay";                                                           /* in zephyr/boards/iar/stm32f429ii_aca/stm32f429ii_aca.dts:204 */
			cs-gpios = < &gpioc 0x2 0x1 >;                                             /* in zephyr/boards/iar/stm32f429ii_aca/stm32f429ii_aca.dts:205 */
		};

		/* node '/soc/spi@40015400' defined in zephyr/dts/arm/st/f4/stm32f427.dtsi:92 */
		spi6: spi@40015400 {
			compatible = "st,stm32-spi";     /* in zephyr/dts/arm/st/f4/stm32f427.dtsi:93 */
			#address-cells = < 0x1 >;        /* in zephyr/dts/arm/st/f4/stm32f427.dtsi:94 */
			#size-cells = < 0x0 >;           /* in zephyr/dts/arm/st/f4/stm32f427.dtsi:95 */
			reg = < 0x40015400 0x400 >;      /* in zephyr/dts/arm/st/f4/stm32f427.dtsi:96 */
			clocks = < &rcc 0x44 0x200000 >; /* in zephyr/dts/arm/st/f4/stm32f427.dtsi:97 */
			interrupts = < 0x56 0x5 >;       /* in zephyr/dts/arm/st/f4/stm32f427.dtsi:98 */
			status = "disabled";             /* in zephyr/dts/arm/st/f4/stm32f427.dtsi:99 */
		};

		/* node '/soc/memory-controller@a0000000' defined in zephyr/dts/arm/st/f4/stm32f427.dtsi:102 */
		fmc: memory-controller@a0000000 {
			compatible = "st,stm32-fmc";                                                                             /* in zephyr/dts/arm/st/f4/stm32f427.dtsi:103 */
			reg = < 0xa0000000 0x400 >;                                                                              /* in zephyr/dts/arm/st/f4/stm32f427.dtsi:104 */
			clocks = < &rcc 0x38 0x1 >;                                                                              /* in zephyr/dts/arm/st/f4/stm32f427.dtsi:105 */
			status = "okay";                                                                                         /* in zephyr/boards/iar/stm32f429ii_aca/stm32f429ii_aca.dts:209 */
			pinctrl-0 = < &fmc_nbl0_pe0 &fmc_nbl1_pe1 &fmc_sdclk_pg8 &fmc_sdnwe_pc0 &fmc_sdcke0_pc3 &fmc_sdne0_pc2
			              &fmc_sdnras_pf11 &fmc_sdncas_pg15 &fmc_a0_pf0 &fmc_a1_pf1 &fmc_a2_pf2 &fmc_a3_pf3
			              &fmc_a4_pf4 &fmc_a5_pf5 &fmc_a6_pf12 &fmc_a7_pf13 &fmc_a8_pf14 &fmc_a9_pf15 &fmc_a10_pg0
			              &fmc_a11_pg1 &fmc_a12_pg2 &fmc_a13_pg3 &fmc_a14_pg4 &fmc_a15_pg5 &fmc_d0_pd14 &fmc_d1_pd15
			              &fmc_d2_pd0 &fmc_d3_pd1 &fmc_d4_pe7 &fmc_d5_pe8 &fmc_d6_pe9 &fmc_d7_pe10 &fmc_d8_pe11
			              &fmc_d9_pe12 &fmc_d10_pe13 &fmc_d11_pe14 &fmc_d12_pe15 &fmc_d13_pd8 &fmc_d14_pd9
			              &fmc_d15_pd10 >;                                                                           /* in zephyr/boards/iar/stm32f429ii_aca/stm32f429ii_aca.dts:210 */
			pinctrl-names = "default";                                                                               /* in zephyr/boards/iar/stm32f429ii_aca/stm32f429ii_aca.dts:221 */

			/* node '/soc/memory-controller@a0000000/sdram' defined in zephyr/dts/arm/st/f4/stm32f427.dtsi:108 */
			sdram: sdram {
				compatible = "st,stm32-fmc-sdram"; /* in zephyr/dts/arm/st/f4/stm32f427.dtsi:109 */
				#address-cells = < 0x1 >;          /* in zephyr/dts/arm/st/f4/stm32f427.dtsi:110 */
				#size-cells = < 0x0 >;             /* in zephyr/dts/arm/st/f4/stm32f427.dtsi:111 */
				status = "okay";                   /* in zephyr/boards/iar/stm32f429ii_aca/stm32f429ii_aca.dts:224 */
				power-up-delay = < 0x64 >;         /* in zephyr/boards/iar/stm32f429ii_aca/stm32f429ii_aca.dts:226 */
				num-auto-refresh = < 0x1 >;        /* in zephyr/boards/iar/stm32f429ii_aca/stm32f429ii_aca.dts:227 */
				mode-register = < 0x0 >;           /* in zephyr/boards/iar/stm32f429ii_aca/stm32f429ii_aca.dts:228 */
				refresh-rate = < 0x56a >;          /* in zephyr/boards/iar/stm32f429ii_aca/stm32f429ii_aca.dts:229 */

				/* node '/soc/memory-controller@a0000000/sdram/bank@1' defined in zephyr/boards/iar/stm32f429ii_aca/stm32f429ii_aca.dts:231 */
				bank@1 {
					reg = < 0x1 >;                                                   /* in zephyr/boards/iar/stm32f429ii_aca/stm32f429ii_aca.dts:232 */
					st,sdram-control = < 0x0 0x4 0x10 0x40 0x100 0xc00 0x0 0x2000 >; /* in zephyr/boards/iar/stm32f429ii_aca/stm32f429ii_aca.dts:234 */
					st,sdram-timing = < 0x2 0x7 0x4 0x7 0x2 0x2 0x2 >;               /* in zephyr/boards/iar/stm32f429ii_aca/stm32f429ii_aca.dts:242 */
				};
			};
		};

		/* node '/soc/sai1@40015804' defined in zephyr/dts/arm/st/f4/stm32f427.dtsi:116 */
		sai1_a: sai1@40015804 {
			compatible = "st,stm32-sai";          /* in zephyr/dts/arm/st/f4/stm32f427.dtsi:117 */
			#address-cells = < 0x1 >;             /* in zephyr/dts/arm/st/f4/stm32f427.dtsi:118 */
			#size-cells = < 0x0 >;                /* in zephyr/dts/arm/st/f4/stm32f427.dtsi:119 */
			reg = < 0x40015804 0x20 >;            /* in zephyr/dts/arm/st/f4/stm32f427.dtsi:120 */
			clocks = < &rcc 0x44 0x400000 >;      /* in zephyr/dts/arm/st/f4/stm32f427.dtsi:121 */
			dmas = < &dma2 0x1 0x0 0x22800 0x0 >; /* in zephyr/dts/arm/st/f4/stm32f427.dtsi:122 */
			status = "disabled";                  /* in zephyr/dts/arm/st/f4/stm32f427.dtsi:124 */
		};

		/* node '/soc/sai1@40015824' defined in zephyr/dts/arm/st/f4/stm32f427.dtsi:127 */
		sai1_b: sai1@40015824 {
			compatible = "st,stm32-sai";          /* in zephyr/dts/arm/st/f4/stm32f427.dtsi:128 */
			#address-cells = < 0x1 >;             /* in zephyr/dts/arm/st/f4/stm32f427.dtsi:129 */
			#size-cells = < 0x0 >;                /* in zephyr/dts/arm/st/f4/stm32f427.dtsi:130 */
			reg = < 0x40015824 0x20 >;            /* in zephyr/dts/arm/st/f4/stm32f427.dtsi:131 */
			clocks = < &rcc 0x44 0x400000 >;      /* in zephyr/dts/arm/st/f4/stm32f427.dtsi:132 */
			dmas = < &dma2 0x5 0x0 0x22800 0x0 >; /* in zephyr/dts/arm/st/f4/stm32f427.dtsi:133 */
			status = "disabled";                  /* in zephyr/dts/arm/st/f4/stm32f427.dtsi:135 */
		};

		/* node '/soc/display-controller@40016800' defined in zephyr/dts/arm/st/f4/stm32f429.dtsi:22 */
		ltdc: display-controller@40016800 {
			compatible = "st,stm32-ltdc";     /* in zephyr/dts/arm/st/f4/stm32f429.dtsi:23 */
			reg = < 0x40016800 0x200 >;       /* in zephyr/dts/arm/st/f4/stm32f429.dtsi:24 */
			interrupts = < 0x58 0x0 >,
			             < 0x59 0x0 >;        /* in zephyr/dts/arm/st/f4/stm32f429.dtsi:25 */
			interrupt-names = "ltdc",
			                  "ltdc_er";      /* in zephyr/dts/arm/st/f4/stm32f429.dtsi:26 */
			clocks = < &rcc 0x44 0x4000000 >; /* in zephyr/dts/arm/st/f4/stm32f429.dtsi:27 */
			resets = < &rctl 0x49a >;         /* in zephyr/dts/arm/st/f4/stm32f429.dtsi:28 */
			status = "disabled";              /* in zephyr/dts/arm/st/f4/stm32f429.dtsi:29 */
		};
	};

	/* node '/cpus' defined in zephyr/dts/arm/st/f4/stm32f4.dtsi:31 */
	cpus {
		#address-cells = < 0x1 >; /* in zephyr/dts/arm/st/f4/stm32f4.dtsi:32 */
		#size-cells = < 0x0 >;    /* in zephyr/dts/arm/st/f4/stm32f4.dtsi:33 */

		/* node '/cpus/cpu@0' defined in zephyr/dts/arm/st/f4/stm32f4.dtsi:35 */
		cpu0: cpu@0 {
			device_type = "cpu";           /* in zephyr/dts/arm/st/f4/stm32f4.dtsi:36 */
			compatible = "arm,cortex-m4f"; /* in zephyr/dts/arm/st/f4/stm32f4.dtsi:37 */
			reg = < 0x0 >;                 /* in zephyr/dts/arm/st/f4/stm32f4.dtsi:38 */
			cpu-power-states = < &stop >;  /* in zephyr/dts/arm/st/f4/stm32f4.dtsi:39 */
		};

		/* node '/cpus/power-states' defined in zephyr/dts/arm/st/f4/stm32f4.dtsi:42 */
		power-states {

			/* node '/cpus/power-states/stop' defined in zephyr/dts/arm/st/f4/stm32f4.dtsi:43 */
			stop: stop {
				compatible = "zephyr,power-state";    /* in zephyr/dts/arm/st/f4/stm32f4.dtsi:44 */
				power-state-name = "suspend-to-idle"; /* in zephyr/dts/arm/st/f4/stm32f4.dtsi:45 */
				min-residency-us = < 0x190 >;         /* in zephyr/dts/arm/st/f4/stm32f4.dtsi:52 */
				exit-latency-us = < 0x12c >;          /* in zephyr/dts/arm/st/f4/stm32f4.dtsi:53 */
				phandle = < 0x3f >;                   /* in zephyr/dts/arm/st/f4/stm32f4.dtsi:39 */
			};
		};
	};

	/* node '/memory@20000000' defined in zephyr/dts/arm/st/f4/stm32f4.dtsi:58 */
	sram0: memory@20000000 {
		compatible = "zephyr,memory-region",
		             "mmio-sram";            /* in zephyr/dts/arm/st/f4/stm32f4.dtsi:59 */
		zephyr,memory-region = "SRAM0";      /* in zephyr/dts/arm/st/f4/stm32f4.dtsi:60 */
		reg = < 0x20000000 0x30000 >;        /* in zephyr/dts/arm/st/f4/stm32f429Xi.dtsi:17 */
	};

	/* node '/clocks' defined in zephyr/dts/arm/st/f4/stm32f4.dtsi:63 */
	clocks {

		/* node '/clocks/clk-hse' defined in zephyr/dts/arm/st/f4/stm32f4.dtsi:64 */
		clk_hse: clk-hse {
			#clock-cells = < 0x0 >;            /* in zephyr/dts/arm/st/f4/stm32f4.dtsi:65 */
			compatible = "st,stm32-hse-clock"; /* in zephyr/dts/arm/st/f4/stm32f4.dtsi:66 */
			clock-frequency = < 0x7a1200 >;    /* in zephyr/boards/iar/stm32f429ii_aca/stm32f429ii_aca.dts:159 */
			status = "okay";                   /* in zephyr/boards/iar/stm32f429ii_aca/stm32f429ii_aca.dts:160 */
			phandle = < 0x40 >;                /* in zephyr/boards/iar/stm32f429ii_aca/stm32f429ii_aca.dts:168 */
		};

		/* node '/clocks/clk-hsi' defined in zephyr/dts/arm/st/f4/stm32f4.dtsi:70 */
		clk_hsi: clk-hsi {
			#clock-cells = < 0x0 >;         /* in zephyr/dts/arm/st/f4/stm32f4.dtsi:71 */
			compatible = "fixed-clock";     /* in zephyr/dts/arm/st/f4/stm32f4.dtsi:72 */
			clock-frequency = < 0xf42400 >; /* in zephyr/dts/arm/st/f4/stm32f4.dtsi:73 */
			status = "disabled";            /* in zephyr/dts/arm/st/f4/stm32f4.dtsi:74 */
		};

		/* node '/clocks/clk-lse' defined in zephyr/dts/arm/st/f4/stm32f4.dtsi:77 */
		clk_lse: clk-lse {
			#clock-cells = < 0x0 >;       /* in zephyr/dts/arm/st/f4/stm32f4.dtsi:78 */
			compatible = "fixed-clock";   /* in zephyr/dts/arm/st/f4/stm32f4.dtsi:79 */
			clock-frequency = < 0x8000 >; /* in zephyr/dts/arm/st/f4/stm32f4.dtsi:80 */
			status = "disabled";          /* in zephyr/dts/arm/st/f4/stm32f4.dtsi:81 */
		};

		/* node '/clocks/clk-lsi' defined in zephyr/dts/arm/st/f4/stm32f4.dtsi:84 */
		clk_lsi: clk-lsi {
			#clock-cells = < 0x0 >;       /* in zephyr/dts/arm/st/f4/stm32f4.dtsi:85 */
			compatible = "fixed-clock";   /* in zephyr/dts/arm/st/f4/stm32f4.dtsi:86 */
			clock-frequency = < 0x7d00 >; /* in zephyr/dts/arm/st/f4/stm32f4.dtsi:87 */
			status = "okay";              /* in zephyr/boards/iar/stm32f429ii_aca/stm32f429ii_aca.dts:155 */
		};

		/* node '/clocks/pll' defined in zephyr/dts/arm/st/f4/stm32f4.dtsi:91 */
		pll: pll {
			#clock-cells = < 0x0 >;              /* in zephyr/dts/arm/st/f4/stm32f4.dtsi:92 */
			compatible = "st,stm32f4-pll-clock"; /* in zephyr/dts/arm/st/f4/stm32f4.dtsi:93 */
			div-m = < 0x8 >;                     /* in zephyr/boards/iar/stm32f429ii_aca/stm32f429ii_aca.dts:164 */
			mul-n = < 0x150 >;                   /* in zephyr/boards/iar/stm32f429ii_aca/stm32f429ii_aca.dts:165 */
			div-p = < 0x2 >;                     /* in zephyr/boards/iar/stm32f429ii_aca/stm32f429ii_aca.dts:166 */
			div-q = < 0x7 >;                     /* in zephyr/boards/iar/stm32f429ii_aca/stm32f429ii_aca.dts:167 */
			clocks = < &clk_hse >;               /* in zephyr/boards/iar/stm32f429ii_aca/stm32f429ii_aca.dts:168 */
			status = "okay";                     /* in zephyr/boards/iar/stm32f429ii_aca/stm32f429ii_aca.dts:169 */
			phandle = < 0x2 >;                   /* in zephyr/boards/iar/stm32f429ii_aca/stm32f429ii_aca.dts:173 */
		};

		/* node '/clocks/plli2s' defined in zephyr/dts/arm/st/f4/stm32f401.dtsi:11 */
		plli2s: plli2s {
			#clock-cells = < 0x0 >;                 /* in zephyr/dts/arm/st/f4/stm32f401.dtsi:12 */
			compatible = "st,stm32f4-plli2s-clock"; /* in zephyr/dts/arm/st/f4/stm32f401.dtsi:13 */
			status = "disabled";                    /* in zephyr/dts/arm/st/f4/stm32f401.dtsi:14 */
		};

		/* node '/clocks/pllsai' defined in zephyr/dts/arm/st/f4/stm32f427.dtsi:14 */
		pllsai: pllsai {
			compatible = "st,stm32fx-pllsai-clock"; /* in zephyr/dts/arm/st/f4/stm32f427.dtsi:15 */
			#clock-cells = < 0x0 >;                 /* in zephyr/dts/arm/st/f4/stm32f427.dtsi:16 */
			status = "disabled";                    /* in zephyr/dts/arm/st/f4/stm32f427.dtsi:17 */
		};
	};

	/* node '/mcos' defined in zephyr/dts/arm/st/f4/stm32f4.dtsi:98 */
	mcos {

		/* node '/mcos/mco1' defined in zephyr/dts/arm/st/f4/stm32f4.dtsi:99 */
		mco1: mco1 {
			compatible = "st,stm32-clock-mco"; /* in zephyr/dts/arm/st/f4/stm32f4.dtsi:100 */
			status = "disabled";               /* in zephyr/dts/arm/st/f4/stm32f4.dtsi:101 */
		};

		/* node '/mcos/mco2' defined in zephyr/dts/arm/st/f4/stm32f4.dtsi:104 */
		mco2: mco2 {
			compatible = "st,stm32-clock-mco"; /* in zephyr/dts/arm/st/f4/stm32f4.dtsi:105 */
			status = "disabled";               /* in zephyr/dts/arm/st/f4/stm32f4.dtsi:106 */
		};
	};

	/* node '/power@40007000' defined in zephyr/dts/arm/st/f4/stm32f4.dtsi:603 */
	pwr: power@40007000 {
		compatible = "st,stm32-pwr"; /* in zephyr/dts/arm/st/f4/stm32f4.dtsi:604 */
		reg = < 0x40007000 0x400 >;  /* in zephyr/dts/arm/st/f4/stm32f4.dtsi:605 */
		status = "disabled";         /* in zephyr/dts/arm/st/f4/stm32f4.dtsi:606 */
		wkup-pins-nb = < 0x1 >;      /* in zephyr/dts/arm/st/f4/stm32f4.dtsi:608 */
		#address-cells = < 0x1 >;    /* in zephyr/dts/arm/st/f4/stm32f4.dtsi:610 */
		#size-cells = < 0x0 >;       /* in zephyr/dts/arm/st/f4/stm32f4.dtsi:611 */

		/* node '/power@40007000/wkup-pin@1' defined in zephyr/dts/arm/st/f4/stm32f4.dtsi:613 */
		wkup-pin@1 {
			reg = < 0x1 >;                   /* in zephyr/dts/arm/st/f4/stm32f4.dtsi:614 */
			wkup-gpios = < &gpioa 0x0 0x1 >; /* in zephyr/dts/arm/st/f4/stm32f4.dtsi:615 */
		};
	};

	/* node '/dietemp' defined in zephyr/dts/arm/st/f4/stm32f4.dtsi:619 */
	die_temp: dietemp {
		compatible = "st,stm32-temp-cal"; /* in zephyr/dts/arm/st/f4/stm32f4.dtsi:620 */
		ts-cal1-addr = < 0x1fff7a2c >;    /* in zephyr/dts/arm/st/f4/stm32f4.dtsi:621 */
		ts-cal2-addr = < 0x1fff7a2e >;    /* in zephyr/dts/arm/st/f4/stm32f4.dtsi:622 */
		ts-cal1-temp = < 0x1e >;          /* in zephyr/dts/arm/st/f4/stm32f4.dtsi:623 */
		ts-cal2-temp = < 0x6e >;          /* in zephyr/dts/arm/st/f4/stm32f4.dtsi:624 */
		ts-cal-vrefanalog = < 0xce4 >;    /* in zephyr/dts/arm/st/f4/stm32f4.dtsi:625 */
		status = "disabled";              /* in zephyr/dts/arm/st/f4/stm32f4.dtsi:627 */
		io-channels = < &adc1 0x12 >;     /* in zephyr/dts/arm/st/f4/stm32f427.dtsi:140 */
	};

	/* node '/vref' defined in zephyr/dts/arm/st/f4/stm32f4.dtsi:630 */
	vref: vref {
		compatible = "st,stm32-vref";      /* in zephyr/dts/arm/st/f4/stm32f4.dtsi:631 */
		vrefint-cal-addr = < 0x1fff7a2a >; /* in zephyr/dts/arm/st/f4/stm32f4.dtsi:632 */
		vrefint-cal-mv = < 0xce4 >;        /* in zephyr/dts/arm/st/f4/stm32f4.dtsi:633 */
		io-channels = < &adc1 0x11 >;      /* in zephyr/dts/arm/st/f4/stm32f4.dtsi:634 */
		status = "disabled";               /* in zephyr/dts/arm/st/f4/stm32f4.dtsi:635 */
	};

	/* node '/vbat' defined in zephyr/dts/arm/st/f4/stm32f4.dtsi:638 */
	vbat: vbat {
		compatible = "st,stm32-vbat"; /* in zephyr/dts/arm/st/f4/stm32f4.dtsi:639 */
		ratio = < 0x4 >;              /* in zephyr/dts/arm/st/f4/stm32f4.dtsi:640 */
		io-channels = < &adc1 0x12 >; /* in zephyr/dts/arm/st/f4/stm32f4.dtsi:641 */
		status = "disabled";          /* in zephyr/dts/arm/st/f4/stm32f4.dtsi:642 */
	};

	/* node '/otgfs_phy' defined in zephyr/dts/arm/st/f4/stm32f4.dtsi:645 */
	otgfs_phy: otgfs_phy {
		compatible = "usb-nop-xceiv"; /* in zephyr/dts/arm/st/f4/stm32f4.dtsi:646 */
		#phy-cells = < 0x0 >;         /* in zephyr/dts/arm/st/f4/stm32f4.dtsi:647 */
		phandle = < 0x9 >;            /* in zephyr/dts/arm/st/f4/stm32f4.dtsi:322 */
	};

	/* node '/smbus1' defined in zephyr/dts/arm/st/f4/stm32f4.dtsi:650 */
	smbus1: smbus1 {
		compatible = "st,stm32-smbus"; /* in zephyr/dts/arm/st/f4/stm32f4.dtsi:651 */
		#address-cells = < 0x1 >;      /* in zephyr/dts/arm/st/f4/stm32f4.dtsi:652 */
		#size-cells = < 0x0 >;         /* in zephyr/dts/arm/st/f4/stm32f4.dtsi:653 */
		i2c = < &i2c1 >;               /* in zephyr/dts/arm/st/f4/stm32f4.dtsi:654 */
		status = "disabled";           /* in zephyr/dts/arm/st/f4/stm32f4.dtsi:655 */
	};

	/* node '/smbus2' defined in zephyr/dts/arm/st/f4/stm32f4.dtsi:658 */
	smbus2: smbus2 {
		compatible = "st,stm32-smbus"; /* in zephyr/dts/arm/st/f4/stm32f4.dtsi:659 */
		#address-cells = < 0x1 >;      /* in zephyr/dts/arm/st/f4/stm32f4.dtsi:660 */
		#size-cells = < 0x0 >;         /* in zephyr/dts/arm/st/f4/stm32f4.dtsi:661 */
		i2c = < &i2c2 >;               /* in zephyr/dts/arm/st/f4/stm32f4.dtsi:662 */
		status = "disabled";           /* in zephyr/dts/arm/st/f4/stm32f4.dtsi:663 */
	};

	/* node '/smbus3' defined in zephyr/dts/arm/st/f4/stm32f4.dtsi:666 */
	smbus3: smbus3 {
		compatible = "st,stm32-smbus"; /* in zephyr/dts/arm/st/f4/stm32f4.dtsi:667 */
		#address-cells = < 0x1 >;      /* in zephyr/dts/arm/st/f4/stm32f4.dtsi:668 */
		#size-cells = < 0x0 >;         /* in zephyr/dts/arm/st/f4/stm32f4.dtsi:669 */
		i2c = < &i2c3 >;               /* in zephyr/dts/arm/st/f4/stm32f4.dtsi:670 */
		status = "disabled";           /* in zephyr/dts/arm/st/f4/stm32f4.dtsi:671 */
	};

	/* node '/otghs_fs_phy' defined in zephyr/dts/arm/st/f4/stm32f405.dtsi:302 */
	otghs_fs_phy: otghs_fs_phy {
		compatible = "usb-nop-xceiv"; /* in zephyr/dts/arm/st/f4/stm32f405.dtsi:303 */
		#phy-cells = < 0x0 >;         /* in zephyr/dts/arm/st/f4/stm32f405.dtsi:304 */
		phandle = < 0xb >;            /* in zephyr/dts/arm/st/f4/stm32f405.dtsi:213 */
	};

	/* node '/memory@10000000' defined in zephyr/dts/arm/st/f4/stm32f429Xi.dtsi:10 */
	ccm0: memory@10000000 {
		compatible = "zephyr,memory-region",
		             "st,stm32-ccm";         /* in zephyr/dts/arm/st/f4/stm32f429Xi.dtsi:11 */
		reg = < 0x10000000 0x10000 >;        /* in zephyr/dts/arm/st/f4/stm32f429Xi.dtsi:12 */
		zephyr,memory-region = "CCM";        /* in zephyr/dts/arm/st/f4/stm32f429Xi.dtsi:13 */
	};

	/* node '/sdram@d0000000' defined in zephyr/boards/iar/stm32f429ii_aca/stm32f429ii_aca.dts:24 */
	sdram2: sdram@d0000000 {
		compatible = "zephyr,memory-region",
		             "mmio-sram";            /* in zephyr/boards/iar/stm32f429ii_aca/stm32f429ii_aca.dts:25 */
		device_type = "memory";              /* in zephyr/boards/iar/stm32f429ii_aca/stm32f429ii_aca.dts:26 */
		reg = < 0xd0000000 0x800000 >;       /* in zephyr/boards/iar/stm32f429ii_aca/stm32f429ii_aca.dts:27 */
		zephyr,memory-region = "SDRAM2";     /* in zephyr/boards/iar/stm32f429ii_aca/stm32f429ii_aca.dts:28 */
	};

	/* node '/leds' defined in zephyr/boards/iar/stm32f429ii_aca/stm32f429ii_aca.dts:31 */
	leds {
		compatible = "gpio-leds"; /* in zephyr/boards/iar/stm32f429ii_aca/stm32f429ii_aca.dts:32 */

		/* node '/leds/led_0' defined in zephyr/boards/iar/stm32f429ii_aca/stm32f429ii_aca.dts:34 */
		traffic_red_led: led_0 {
			gpios = < &gpioa 0x4 0x1 >; /* in zephyr/boards/iar/stm32f429ii_aca/stm32f429ii_aca.dts:35 */
			label = "LED0";             /* in zephyr/boards/iar/stm32f429ii_aca/stm32f429ii_aca.dts:36 */
		};

		/* node '/leds/led_1' defined in zephyr/boards/iar/stm32f429ii_aca/stm32f429ii_aca.dts:39 */
		traffic_yellow_led: led_1 {
			gpios = < &gpiod 0x4 0x1 >; /* in zephyr/boards/iar/stm32f429ii_aca/stm32f429ii_aca.dts:40 */
			label = "LED1";             /* in zephyr/boards/iar/stm32f429ii_aca/stm32f429ii_aca.dts:41 */
		};

		/* node '/leds/led_2' defined in zephyr/boards/iar/stm32f429ii_aca/stm32f429ii_aca.dts:44 */
		traffic_green_led: led_2 {
			gpios = < &gpiod 0x5 0x1 >; /* in zephyr/boards/iar/stm32f429ii_aca/stm32f429ii_aca.dts:45 */
			label = "LED2";             /* in zephyr/boards/iar/stm32f429ii_aca/stm32f429ii_aca.dts:46 */
		};

		/* node '/leds/led_3' defined in zephyr/boards/iar/stm32f429ii_aca/stm32f429ii_aca.dts:49 */
		car_led: led_3 {
			gpios = < &gpiod 0x6 0x1 >; /* in zephyr/boards/iar/stm32f429ii_aca/stm32f429ii_aca.dts:50 */
			label = "LED3";             /* in zephyr/boards/iar/stm32f429ii_aca/stm32f429ii_aca.dts:51 */
		};

		/* node '/leds/led_4' defined in zephyr/boards/iar/stm32f429ii_aca/stm32f429ii_aca.dts:54 */
		pedestrian_red_led: led_4 {
			gpios = < &gpiod 0x7 0x1 >; /* in zephyr/boards/iar/stm32f429ii_aca/stm32f429ii_aca.dts:55 */
			label = "LED4";             /* in zephyr/boards/iar/stm32f429ii_aca/stm32f429ii_aca.dts:56 */
		};

		/* node '/leds/led_5' defined in zephyr/boards/iar/stm32f429ii_aca/stm32f429ii_aca.dts:59 */
		pedestrian_green_led: led_5 {
			gpios = < &gpiod 0xb 0x1 >; /* in zephyr/boards/iar/stm32f429ii_aca/stm32f429ii_aca.dts:60 */
			label = "LED5";             /* in zephyr/boards/iar/stm32f429ii_aca/stm32f429ii_aca.dts:61 */
		};

		/* node '/leds/led_6' defined in zephyr/boards/iar/stm32f429ii_aca/stm32f429ii_aca.dts:64 */
		user_led_1: led_6 {
			gpios = < &gpiod 0xc 0x1 >; /* in zephyr/boards/iar/stm32f429ii_aca/stm32f429ii_aca.dts:65 */
			label = "LED6";             /* in zephyr/boards/iar/stm32f429ii_aca/stm32f429ii_aca.dts:66 */
		};

		/* node '/leds/led_7' defined in zephyr/boards/iar/stm32f429ii_aca/stm32f429ii_aca.dts:69 */
		user_led_2: led_7 {
			gpios = < &gpiod 0xd 0x1 >; /* in zephyr/boards/iar/stm32f429ii_aca/stm32f429ii_aca.dts:70 */
			label = "LED7";             /* in zephyr/boards/iar/stm32f429ii_aca/stm32f429ii_aca.dts:71 */
		};
	};

	/* node '/gpio_keys' defined in zephyr/boards/iar/stm32f429ii_aca/stm32f429ii_aca.dts:75 */
	gpio_keys {
		compatible = "gpio-keys"; /* in zephyr/boards/iar/stm32f429ii_aca/stm32f429ii_aca.dts:76 */

		/* node '/gpio_keys/button_0' defined in zephyr/boards/iar/stm32f429ii_aca/stm32f429ii_aca.dts:78 */
		button0: button_0 {
			label = "BUT0";             /* in zephyr/boards/iar/stm32f429ii_aca/stm32f429ii_aca.dts:79 */
			gpios = < &gpioa 0x0 0x1 >; /* in zephyr/boards/iar/stm32f429ii_aca/stm32f429ii_aca.dts:80 */
			zephyr,code = < 0xb >;      /* in zephyr/boards/iar/stm32f429ii_aca/stm32f429ii_aca.dts:81 */
		};

		/* node '/gpio_keys/button_1' defined in zephyr/boards/iar/stm32f429ii_aca/stm32f429ii_aca.dts:84 */
		button1: button_1 {
			label = "BUT1";             /* in zephyr/boards/iar/stm32f429ii_aca/stm32f429ii_aca.dts:85 */
			gpios = < &gpioc 0xd 0x1 >; /* in zephyr/boards/iar/stm32f429ii_aca/stm32f429ii_aca.dts:86 */
			zephyr,code = < 0x2 >;      /* in zephyr/boards/iar/stm32f429ii_aca/stm32f429ii_aca.dts:87 */
		};

		/* node '/gpio_keys/button_2' defined in zephyr/boards/iar/stm32f429ii_aca/stm32f429ii_aca.dts:90 */
		button2: button_2 {
			label = "BUT2";             /* in zephyr/boards/iar/stm32f429ii_aca/stm32f429ii_aca.dts:91 */
			gpios = < &gpiog 0x9 0x1 >; /* in zephyr/boards/iar/stm32f429ii_aca/stm32f429ii_aca.dts:92 */
			zephyr,code = < 0x3 >;      /* in zephyr/boards/iar/stm32f429ii_aca/stm32f429ii_aca.dts:93 */
		};

		/* node '/gpio_keys/switch_0' defined in zephyr/boards/iar/stm32f429ii_aca/stm32f429ii_aca.dts:96 */
		open_close_switch: switch_0 {
			label = "OPEN/CLOSE SWITCH"; /* in zephyr/boards/iar/stm32f429ii_aca/stm32f429ii_aca.dts:97 */
			gpios = < &gpioi 0xb 0x0 >;  /* in zephyr/boards/iar/stm32f429ii_aca/stm32f429ii_aca.dts:98 */
			zephyr,code = < 0x4 >;       /* in zephyr/boards/iar/stm32f429ii_aca/stm32f429ii_aca.dts:99 */
		};

		/* node '/gpio_keys/switch_1' defined in zephyr/boards/iar/stm32f429ii_aca/stm32f429ii_aca.dts:102 */
		interior_light_switch_on: switch_1 {
			label = "ON";               /* in zephyr/boards/iar/stm32f429ii_aca/stm32f429ii_aca.dts:103 */
			gpios = < &gpioi 0xa 0x1 >; /* in zephyr/boards/iar/stm32f429ii_aca/stm32f429ii_aca.dts:104 */
			zephyr,code = < 0x5 >;      /* in zephyr/boards/iar/stm32f429ii_aca/stm32f429ii_aca.dts:105 */
		};

		/* node '/gpio_keys/switch_2' defined in zephyr/boards/iar/stm32f429ii_aca/stm32f429ii_aca.dts:108 */
		interior_light_switch_auto: switch_2 {
			label = "AUTO";             /* in zephyr/boards/iar/stm32f429ii_aca/stm32f429ii_aca.dts:109 */
			gpios = < &gpioi 0x9 0x1 >; /* in zephyr/boards/iar/stm32f429ii_aca/stm32f429ii_aca.dts:110 */
			zephyr,code = < 0x6 >;      /* in zephyr/boards/iar/stm32f429ii_aca/stm32f429ii_aca.dts:111 */
		};

		/* node '/gpio_keys/switch_3' defined in zephyr/boards/iar/stm32f429ii_aca/stm32f429ii_aca.dts:114 */
		interior_light_switch_off: switch_3 {
			label = "OFF";              /* in zephyr/boards/iar/stm32f429ii_aca/stm32f429ii_aca.dts:115 */
			gpios = < &gpioi 0x8 0x1 >; /* in zephyr/boards/iar/stm32f429ii_aca/stm32f429ii_aca.dts:116 */
			zephyr,code = < 0x7 >;      /* in zephyr/boards/iar/stm32f429ii_aca/stm32f429ii_aca.dts:117 */
		};

		/* node '/gpio_keys/cap_button_0' defined in zephyr/boards/iar/stm32f429ii_aca/stm32f429ii_aca.dts:120 */
		cap_button0: cap_button_0 {
			label = "CAP_BUT0";         /* in zephyr/boards/iar/stm32f429ii_aca/stm32f429ii_aca.dts:121 */
			gpios = < &gpioh 0x6 0x1 >; /* in zephyr/boards/iar/stm32f429ii_aca/stm32f429ii_aca.dts:122 */
			zephyr,code = < 0x8 >;      /* in zephyr/boards/iar/stm32f429ii_aca/stm32f429ii_aca.dts:123 */
		};

		/* node '/gpio_keys/cap_button_1' defined in zephyr/boards/iar/stm32f429ii_aca/stm32f429ii_aca.dts:126 */
		cap_button1: cap_button_1 {
			label = "CAP_BUT1";         /* in zephyr/boards/iar/stm32f429ii_aca/stm32f429ii_aca.dts:127 */
			gpios = < &gpioh 0x7 0x1 >; /* in zephyr/boards/iar/stm32f429ii_aca/stm32f429ii_aca.dts:128 */
			zephyr,code = < 0x9 >;      /* in zephyr/boards/iar/stm32f429ii_aca/stm32f429ii_aca.dts:129 */
		};
	};
};
